AUTOSAR XML (schema 00050)
package /MICROSAR/NvM_swc/DataTypes
  impl type NvM_RequestResultType: compu {0=NVM_REQ_OK, 1=NVM_REQ_NOT_OK, 2=NVM_REQ_PENDING, 3=NVM_REQ_INTEGRITY_FAILED, 4=NVM_REQ_BLOCK_SKIPPED, 5=NVM_REQ_NV_INVALIDATED, 6=NVM_REQ_CANCELED, 7=NVM_REQ_REDUNDANCY_FAILED, 8=NVM_REQ_RESTORED_FROM_ROM}, range raw 0..8, implementation-data-type=uint8
  impl type NvM_BlockIdType: range raw 1..32767, implementation-data-type=uint16
  impl type NvM_ServiceIdType: compu {6=NVM_READ_BLOCK, 7=NVM_WRITE_BLOCK, 8=NVM_RESTORE_BLOCK_DEFAULTS, 9=NVM_ERASE_BLOCK, 11=NVM_INVALIDATE_NV_BLOCK, 12=NVM_READ_ALL}, range raw 6..12, implementation-data-type=uint8
package /MICROSAR/NvM_swc/Interfaces
  4 x client server interface, all with is-service=true, service-kind=NON-VOLATILE-RAM-MANAGER:
    NvMAdministration
      operation SetBlockProtection: possible-error=NvMAdministration/E_NOT_OK
        arg ProtectionEnabled: type=boolean, direction=IN
      error E_NOT_OK: error-code=1
    NvMService_AC3_SRBS_DS
      8 x operation, all with possible-error=NvMService_AC3_SRBS_DS/E_NOT_OK:
        GetErrorStatus
          arg ErrorStatus: type=NvM_RequestResultType, direction=OUT
        SetRamBlockStatus
          arg RamBlockStatus: type=boolean, direction=IN
        ReadBlock
          arg DstPtr: type=dtRef_VOID, direction=IN
        WriteBlock
          arg SrcPtr: type=dtRef_const_VOID, direction=IN
        SetDataIndex
          arg DataIndex: type=uint8, direction=IN
        GetDataIndex
          arg DataIndex: type=uint8, direction=OUT
        InvalidateNvBlock
        EraseBlock
      error E_NOT_OK: error-code=1
    NvMNotifyJobFinished
      operation JobFinished
        arg ServiceId: type=NvM_ServiceIdType, direction=IN
        arg JobResult: type=NvM_RequestResultType, direction=IN
    NvMService_AC3_SRBS_Defs
      7 x operation, all with possible-error=NvMService_AC3_SRBS_Defs/E_NOT_OK:
        GetErrorStatus
          arg ErrorStatus: type=NvM_RequestResultType, direction=OUT
        SetRamBlockStatus
          arg RamBlockStatus: type=boolean, direction=IN
        ReadBlock
          arg DstPtr: type=dtRef_VOID, direction=IN
        WriteBlock
          arg SrcPtr: type=dtRef_const_VOID, direction=IN
        RestoreBlockDefaults
          arg DstPtr: type=dtRef_VOID, direction=IN
        InvalidateNvBlock
        EraseBlock
      error E_NOT_OK: error-code=1
package /MICROSAR/NvM_swc/ComponentTypes
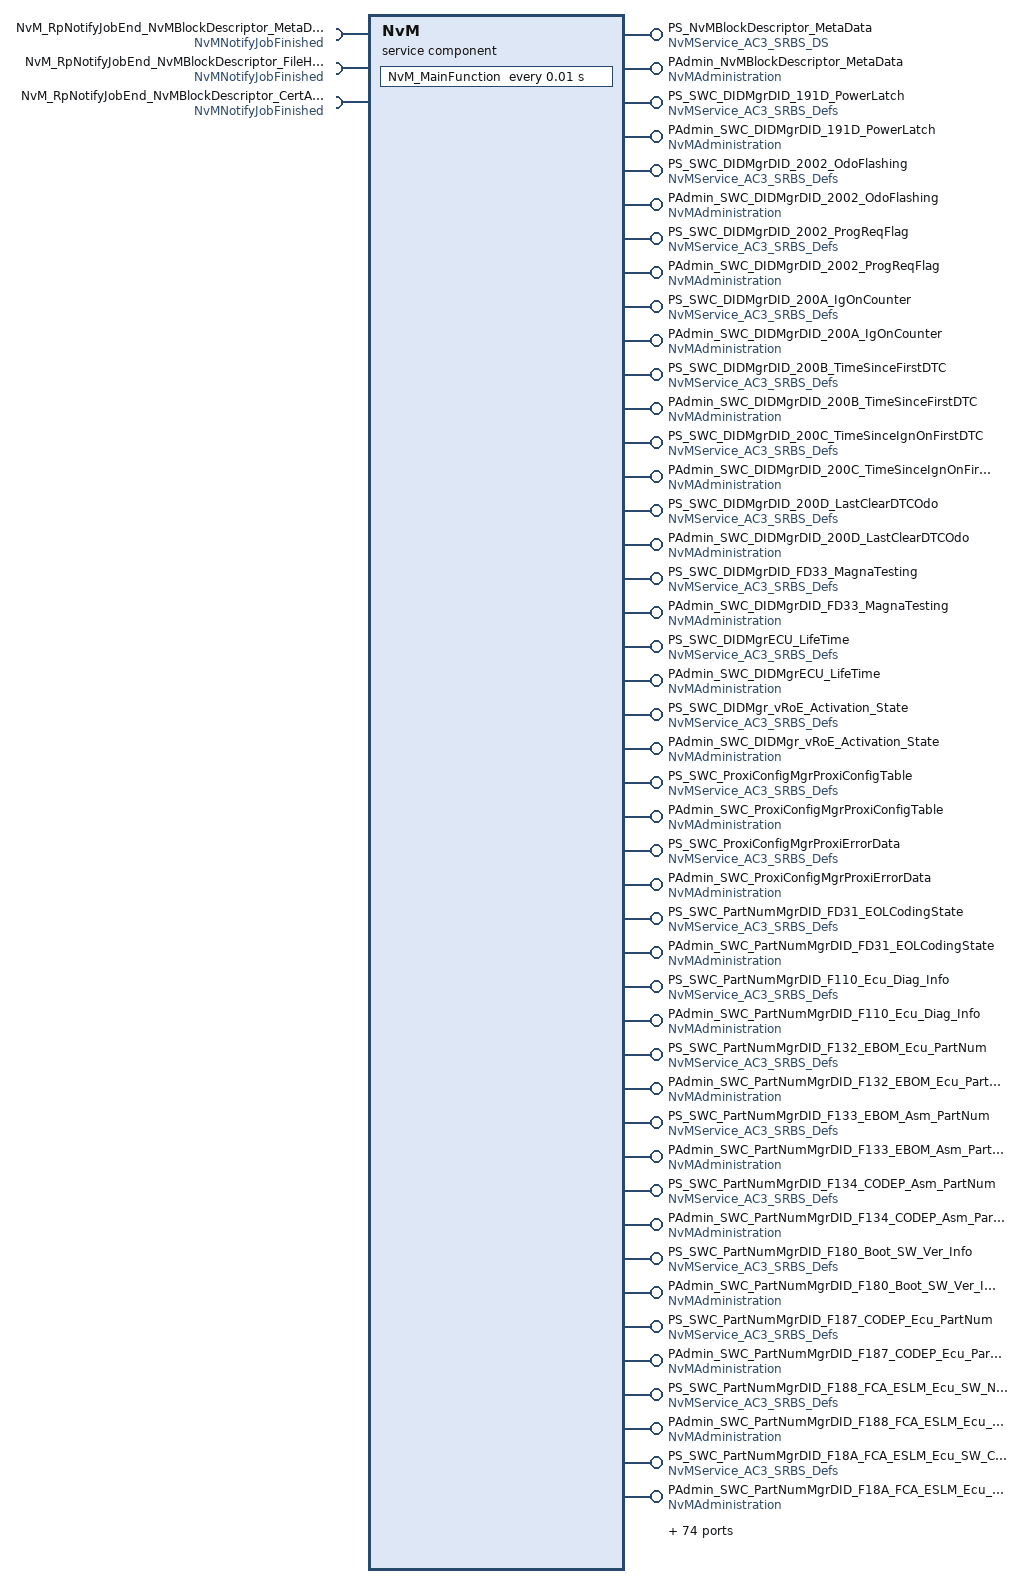
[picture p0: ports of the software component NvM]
  service sw component type NvM: category=SERVICE_COMPONENT
    provide port PS_NvMBlockDescriptor_MetaData: provided-interface=NvMService_AC3_SRBS_DS
    provide port PAdmin_NvMBlockDescriptor_MetaData: provided-interface=NvMAdministration
    require port NvM_RpNotifyJobEnd_NvMBlockDescriptor_MetaData: required-interface=NvMNotifyJobFinished
    86 x provide port:
      PS_SWC_DIDMgrDID_191D_PowerLatch: provided-interface=NvMService_AC3_SRBS_Defs
      PAdmin_SWC_DIDMgrDID_191D_PowerLatch: provided-interface=NvMAdministration
      PS_SWC_DIDMgrDID_2002_OdoFlashing: provided-interface=NvMService_AC3_SRBS_Defs
      PAdmin_SWC_DIDMgrDID_2002_OdoFlashing: provided-interface=NvMAdministration
      PS_SWC_DIDMgrDID_2002_ProgReqFlag: provided-interface=NvMService_AC3_SRBS_Defs
      PAdmin_SWC_DIDMgrDID_2002_ProgReqFlag: provided-interface=NvMAdministration
      PS_SWC_DIDMgrDID_200A_IgOnCounter: provided-interface=NvMService_AC3_SRBS_Defs
      PAdmin_SWC_DIDMgrDID_200A_IgOnCounter: provided-interface=NvMAdministration
      PS_SWC_DIDMgrDID_200B_TimeSinceFirstDTC: provided-interface=NvMService_AC3_SRBS_Defs
      PAdmin_SWC_DIDMgrDID_200B_TimeSinceFirstDTC: provided-interface=NvMAdministration
      PS_SWC_DIDMgrDID_200C_TimeSinceIgnOnFirstDTC: provided-interface=NvMService_AC3_SRBS_Defs
      PAdmin_SWC_DIDMgrDID_200C_TimeSinceIgnOnFirstDTC: provided-interface=NvMAdministration
      PS_SWC_DIDMgrDID_200D_LastClearDTCOdo: provided-interface=NvMService_AC3_SRBS_Defs
      PAdmin_SWC_DIDMgrDID_200D_LastClearDTCOdo: provided-interface=NvMAdministration
      PS_SWC_DIDMgrDID_FD33_MagnaTesting: provided-interface=NvMService_AC3_SRBS_Defs
      PAdmin_SWC_DIDMgrDID_FD33_MagnaTesting: provided-interface=NvMAdministration
      PS_SWC_DIDMgrECU_LifeTime: provided-interface=NvMService_AC3_SRBS_Defs
      PAdmin_SWC_DIDMgrECU_LifeTime: provided-interface=NvMAdministration
      PS_SWC_DIDMgr_vRoE_Activation_State: provided-interface=NvMService_AC3_SRBS_Defs
      PAdmin_SWC_DIDMgr_vRoE_Activation_State: provided-interface=NvMAdministration
      PS_SWC_ProxiConfigMgrProxiConfigTable: provided-interface=NvMService_AC3_SRBS_Defs
      PAdmin_SWC_ProxiConfigMgrProxiConfigTable: provided-interface=NvMAdministration
      PS_SWC_ProxiConfigMgrProxiErrorData: provided-interface=NvMService_AC3_SRBS_Defs
      PAdmin_SWC_ProxiConfigMgrProxiErrorData: provided-interface=NvMAdministration
      PS_SWC_PartNumMgrDID_FD31_EOLCodingState: provided-interface=NvMService_AC3_SRBS_Defs
      PAdmin_SWC_PartNumMgrDID_FD31_EOLCodingState: provided-interface=NvMAdministration
      PS_SWC_PartNumMgrDID_F110_Ecu_Diag_Info: provided-interface=NvMService_AC3_SRBS_Defs
      PAdmin_SWC_PartNumMgrDID_F110_Ecu_Diag_Info: provided-interface=NvMAdministration
      PS_SWC_PartNumMgrDID_F132_EBOM_Ecu_PartNum: provided-interface=NvMService_AC3_SRBS_Defs
      PAdmin_SWC_PartNumMgrDID_F132_EBOM_Ecu_PartNum: provided-interface=NvMAdministration
      PS_SWC_PartNumMgrDID_F133_EBOM_Asm_PartNum: provided-interface=NvMService_AC3_SRBS_Defs
      PAdmin_SWC_PartNumMgrDID_F133_EBOM_Asm_PartNum: provided-interface=NvMAdministration
      PS_SWC_PartNumMgrDID_F134_CODEP_Asm_PartNum: provided-interface=NvMService_AC3_SRBS_Defs
      PAdmin_SWC_PartNumMgrDID_F134_CODEP_Asm_PartNum: provided-interface=NvMAdministration
      PS_SWC_PartNumMgrDID_F180_Boot_SW_Ver_Info: provided-interface=NvMService_AC3_SRBS_Defs
      PAdmin_SWC_PartNumMgrDID_F180_Boot_SW_Ver_Info: provided-interface=NvMAdministration
      PS_SWC_PartNumMgrDID_F187_CODEP_Ecu_PartNum: provided-interface=NvMService_AC3_SRBS_Defs
      PAdmin_SWC_PartNumMgrDID_F187_CODEP_Ecu_PartNum: provided-interface=NvMAdministration
      PS_SWC_PartNumMgrDID_F188_FCA_ESLM_Ecu_SW_Num: provided-interface=NvMService_AC3_SRBS_Defs
      PAdmin_SWC_PartNumMgrDID_F188_FCA_ESLM_Ecu_SW_Num: provided-interface=NvMAdministration
      PS_SWC_PartNumMgrDID_F18A_FCA_ESLM_Ecu_SW_Cal_Num: provided-interface=NvMService_AC3_SRBS_Defs
      PAdmin_SWC_PartNumMgrDID_F18A_FCA_ESLM_Ecu_SW_Cal_Num: provided-interface=NvMAdministration
      PS_SWC_PartNumMgrDID_F18B_FCA_ESLM_ECU_SW_App_Num: provided-interface=NvMService_AC3_SRBS_Defs
      PAdmin_SWC_PartNumMgrDID_F18B_FCA_ESLM_ECU_SW_App_Num: provided-interface=NvMAdministration
      PS_SWC_PartNumMgrDID_F194_Supplier_Ecu_SW_PartNum: provided-interface=NvMService_AC3_SRBS_Defs
      PAdmin_SWC_PartNumMgrDID_F194_Supplier_Ecu_SW_PartNum: provided-interface=NvMAdministration
      PS_SWC_PartNumMgrDID_F195_Supplier_Ecu_SW_VerNum: provided-interface=NvMService_AC3_SRBS_Defs
      PAdmin_SWC_PartNumMgrDID_F195_Supplier_Ecu_SW_VerNum: provided-interface=NvMAdministration
      PS_CalDataProviderSVSCamCurrentCalibData: provided-interface=NvMService_AC3_SRBS_Defs
      PAdmin_CalDataProviderSVSCamCurrentCalibData: provided-interface=NvMAdministration
      PS_CalDataProviderSVSCamEOLCalibData: provided-interface=NvMService_AC3_SRBS_Defs
      PAdmin_CalDataProviderSVSCamEOLCalibData: provided-interface=NvMAdministration
      PS_CalDataProviderSVSCamOCCalibData: provided-interface=NvMService_AC3_SRBS_Defs
      PAdmin_CalDataProviderSVSCamOCCalibData: provided-interface=NvMAdministration
      PS_CalDataProviderSVSCamSCCalibData: provided-interface=NvMService_AC3_SRBS_Defs
      PAdmin_CalDataProviderSVSCamSCCalibData: provided-interface=NvMAdministration
      PS_SWC_PartNumMgrUssSensorMarrData: provided-interface=NvMService_AC3_SRBS_Defs
      PAdmin_SWC_PartNumMgrUssSensorMarrData: provided-interface=NvMAdministration
      PS_SWC_DIDMgrDID_FD01_PrevCalibDataCopy: provided-interface=NvMService_AC3_SRBS_Defs
      PAdmin_SWC_DIDMgrDID_FD01_PrevCalibDataCopy: provided-interface=NvMAdministration
      PS_SWC_DIDMgrDID_FD42_FailsafeDebug: provided-interface=NvMService_AC3_SRBS_Defs
      PAdmin_SWC_DIDMgrDID_FD42_FailsafeDebug: provided-interface=NvMAdministration
      PS_SWC_DIDMgrDID_RearBrakeEvent: provided-interface=NvMService_AC3_SRBS_Defs
      PAdmin_SWC_DIDMgrDID_RearBrakeEvent: provided-interface=NvMAdministration
      PS_SWC_DIDMgrDID_SPMAbrtEvent: provided-interface=NvMService_AC3_SRBS_Defs
      PAdmin_SWC_DIDMgrDID_SPMAbrtEvent: provided-interface=NvMAdministration
      PS_CDD_IPCHandlerFeatureAP_HMI_NvMData: provided-interface=NvMService_AC3_SRBS_Defs
      PAdmin_CDD_IPCHandlerFeatureAP_HMI_NvMData: provided-interface=NvMAdministration
      PS_SWC_DIDMgrDID_FD86_FunctionalSettings: provided-interface=NvMService_AC3_SRBS_Defs
      PAdmin_SWC_DIDMgrDID_FD86_FunctionalSettings: provided-interface=NvMAdministration
      PS_SWC_DIDMgrDID_2939_WakeupReason: provided-interface=NvMService_AC3_SRBS_Defs
      PAdmin_SWC_DIDMgrDID_2939_WakeupReason: provided-interface=NvMAdministration
      PS_SWC_DIDMgrDID_FDF0_SleepProcess: provided-interface=NvMService_AC3_SRBS_Defs
      PAdmin_SWC_DIDMgrDID_FDF0_SleepProcess: provided-interface=NvMAdministration
      PS_SWC_RIDMgrDID_5201_PlantModeStatus: provided-interface=NvMService_AC3_SRBS_Defs
      PAdmin_SWC_RIDMgrDID_5201_PlantModeStatus: provided-interface=NvMAdministration
      PS_SWC_RIDMgrVIN_CurrentVal: provided-interface=NvMService_AC3_SRBS_Defs
      PAdmin_SWC_RIDMgrVIN_CurrentVal: provided-interface=NvMAdministration
      PS_SWC_RIDMgrVIN_Lock: provided-interface=NvMService_AC3_SRBS_Defs
      PAdmin_SWC_RIDMgrVIN_Lock: provided-interface=NvMAdministration
      PS_SWC_RIDMgrVIN_OdometerCnt: provided-interface=NvMService_AC3_SRBS_Defs
      PAdmin_SWC_RIDMgrVIN_OdometerCnt: provided-interface=NvMAdministration
      PS_SWC_RIDMgrVIN_OriginalVal: provided-interface=NvMService_AC3_SRBS_Defs
      PAdmin_SWC_RIDMgrVIN_OriginalVal: provided-interface=NvMAdministration
      PS_NvMBlockDescriptor_FileHeader: provided-interface=NvMService_AC3_SRBS_DS
      PAdmin_NvMBlockDescriptor_FileHeader: provided-interface=NvMAdministration
    require port NvM_RpNotifyJobEnd_NvMBlockDescriptor_FileHeader: required-interface=NvMNotifyJobFinished
    require port NvM_RpNotifyJobEnd_NvMBlockDescriptor_CertAccessInfo: required-interface=NvMNotifyJobFinished
    30 x provide port:
      PS_CDD_IPCHandlerFPA_SlotData: provided-interface=NvMService_AC3_SRBS_Defs
      PAdmin_CDD_IPCHandlerFPA_SlotData: provided-interface=NvMAdministration
      PS_CDD_CryptoMgrNvMBlockDescriptor_SecAccessDelayFlag: provided-interface=NvMService_AC3_SRBS_Defs
      PAdmin_CDD_CryptoMgrNvMBlockDescriptor_SecAccessDelayFlag: provided-interface=NvMAdministration
      PS_CDD_CryptoMgrNvMBlockDescriptor_SecAccessInvalidCount: provided-interface=NvMService_AC3_SRBS_Defs
      PAdmin_CDD_CryptoMgrNvMBlockDescriptor_SecAccessInvalidCount: provided-interface=NvMAdministration
      PS_NvMBlockDescriptor_CertAccessInfo: provided-interface=NvMService_AC3_SRBS_DS
      PAdmin_NvMBlockDescriptor_CertAccessInfo: provided-interface=NvMAdministration
      PS_CDD_CryptoMgrNvMBlockDescriptor_SecureLogGroup1: provided-interface=NvMService_AC3_SRBS_Defs
      PAdmin_CDD_CryptoMgrNvMBlockDescriptor_SecureLogGroup1: provided-interface=NvMAdministration
      PS_CDD_CryptoMgrNvMBlockDescriptor_SecureLogGroup2: provided-interface=NvMService_AC3_SRBS_Defs
      PAdmin_CDD_CryptoMgrNvMBlockDescriptor_SecureLogGroup2: provided-interface=NvMAdministration
      PS_Safety_GuardSafeStat2_ResetReason: provided-interface=NvMService_AC3_SRBS_Defs
      PAdmin_Safety_GuardSafeStat2_ResetReason: provided-interface=NvMAdministration
      PS_CalDataProviderFrontCamSerialNumber: provided-interface=NvMService_AC3_SRBS_Defs
      PAdmin_CalDataProviderFrontCamSerialNumber: provided-interface=NvMAdministration
      PS_CalDataProviderLeftCamSerialNumber: provided-interface=NvMService_AC3_SRBS_Defs
      PAdmin_CalDataProviderLeftCamSerialNumber: provided-interface=NvMAdministration
      PS_CalDataProviderRearCamSerialNumber: provided-interface=NvMService_AC3_SRBS_Defs
      PAdmin_CalDataProviderRearCamSerialNumber: provided-interface=NvMAdministration
      PS_CalDataProviderRightCamSerialNumber: provided-interface=NvMService_AC3_SRBS_Defs
      PAdmin_CalDataProviderRightCamSerialNumber: provided-interface=NvMAdministration
      PS_CDD_SafetyCDD_PMICLastResetReason_BISTStatus: provided-interface=NvMService_AC3_SRBS_Defs
      PAdmin_CDD_SafetyCDD_PMICLastResetReason_BISTStatus: provided-interface=NvMAdministration
      PS_SWC_DIDMgrDID_FD74_BuffMarkCompErr: provided-interface=NvMService_AC3_SRBS_Defs
      PAdmin_SWC_DIDMgrDID_FD74_BuffMarkCompErr: provided-interface=NvMAdministration
      PS_SWC_DIDMgrDID_FD74_PHY_TuningErr: provided-interface=NvMService_AC3_SRBS_Defs
      PAdmin_SWC_DIDMgrDID_FD74_PHY_TuningErr: provided-interface=NvMAdministration
      PS_SWC_DTCMgrDTC_APARequestSts_PAMRequestSts: provided-interface=NvMService_AC3_SRBS_Defs
      PAdmin_SWC_DTCMgrDTC_APARequestSts_PAMRequestSts: provided-interface=NvMAdministration
    behavior NvMInternalBehavior: handle-termination-and-restart=NO-SUPPORT
      timing event Timer_NvM_MainFunction: start-on-event=NvM_MainFunction, period=0.01
      475 x operation invoked event:
        OpEventGetErrorStatus_GetErrorStatus_PS_NvMBlockDescriptor_MetaData: start-on-event=GetErrorStatus, operation=PS_NvMBlockDescriptor_MetaData.GetErrorStatus
        OpEventSetRamBlockStatus_SetRamBlockStatus_PS_NvMBlockDescriptor_MetaData: start-on-event=SetRamBlockStatus, operation=PS_NvMBlockDescriptor_MetaData.SetRamBlockStatus
        OpEventReadBlock_ReadBlock_PS_NvMBlockDescriptor_MetaData: start-on-event=ReadBlock, operation=PS_NvMBlockDescriptor_MetaData.ReadBlock
        OpEventWriteBlock_WriteBlock_PS_NvMBlockDescriptor_MetaData: start-on-event=WriteBlock, operation=PS_NvMBlockDescriptor_MetaData.WriteBlock
        OpEventSetDataIndex_SetDataIndex_PS_NvMBlockDescriptor_MetaData: start-on-event=SetDataIndex, operation=PS_NvMBlockDescriptor_MetaData.SetDataIndex
        OpEventGetDataIndex_GetDataIndex_PS_NvMBlockDescriptor_MetaData: start-on-event=GetDataIndex, operation=PS_NvMBlockDescriptor_MetaData.GetDataIndex
        OpEventInvalidateNvBlock_InvalidateNvBlock_PS_NvMBlockDescriptor_MetaData: start-on-event=InvalidateNvBlock, operation=PS_NvMBlockDescriptor_MetaData.InvalidateNvBlock
        OpEventEraseBlock_EraseBlock_PS_NvMBlockDescriptor_MetaData: start-on-event=EraseBlock, operation=PS_NvMBlockDescriptor_MetaData.EraseBlock
        OpEventSetBlockProtection_SetBlockProtection_PAdmin_NvMBlockDescriptor_MetaData: start-on-event=SetBlockProtection, operation=PAdmin_NvMBlockDescriptor_MetaData.SetBlockProtection
        OpEventGetErrorStatus_GetErrorStatus_PS_SWC_DIDMgrDID_191D_PowerLatch: start-on-event=GetErrorStatus, operation=PS_SWC_DIDMgrDID_191D_PowerLatch.GetErrorStatus
        OpEventGetErrorStatus_GetErrorStatus_PS_SWC_DIDMgrDID_2002_OdoFlashing: start-on-event=GetErrorStatus, operation=PS_SWC_DIDMgrDID_2002_OdoFlashing.GetErrorStatus
        OpEventGetErrorStatus_GetErrorStatus_PS_SWC_DIDMgrDID_2002_ProgReqFlag: start-on-event=GetErrorStatus, operation=PS_SWC_DIDMgrDID_2002_ProgReqFlag.GetErrorStatus
        OpEventGetErrorStatus_GetErrorStatus_PS_SWC_DIDMgrDID_200A_IgOnCounter: start-on-event=GetErrorStatus, operation=PS_SWC_DIDMgrDID_200A_IgOnCounter.GetErrorStatus
        OpEventGetErrorStatus_GetErrorStatus_PS_SWC_DIDMgrDID_200B_TimeSinceFirstDTC: start-on-event=GetErrorStatus, operation=PS_SWC_DIDMgrDID_200B_TimeSinceFirstDTC.GetErrorStatus
        OpEventGetErrorStatus_GetErrorStatus_PS_SWC_DIDMgrDID_200C_TimeSinceIgnOnFirstDTC: start-on-event=GetErrorStatus, operation=PS_SWC_DIDMgrDID_200C_TimeSinceIgnOnFirstDTC.GetErrorStatus
        OpEventGetErrorStatus_GetErrorStatus_PS_SWC_DIDMgrDID_200D_LastClearDTCOdo: start-on-event=GetErrorStatus, operation=PS_SWC_DIDMgrDID_200D_LastClearDTCOdo.GetErrorStatus
        OpEventGetErrorStatus_GetErrorStatus_PS_SWC_DIDMgrDID_FD33_MagnaTesting: start-on-event=GetErrorStatus, operation=PS_SWC_DIDMgrDID_FD33_MagnaTesting.GetErrorStatus
        OpEventGetErrorStatus_GetErrorStatus_PS_SWC_DIDMgrECU_LifeTime: start-on-event=GetErrorStatus, operation=PS_SWC_DIDMgrECU_LifeTime.GetErrorStatus
        OpEventGetErrorStatus_GetErrorStatus_PS_SWC_DIDMgr_vRoE_Activation_State: start-on-event=GetErrorStatus, operation=PS_SWC_DIDMgr_vRoE_Activation_State.GetErrorStatus
        OpEventSetRamBlockStatus_SetRamBlockStatus_PS_SWC_DIDMgrDID_191D_PowerLatch: start-on-event=SetRamBlockStatus, operation=PS_SWC_DIDMgrDID_191D_PowerLatch.SetRamBlockStatus
        OpEventSetRamBlockStatus_SetRamBlockStatus_PS_SWC_DIDMgrDID_2002_OdoFlashing: start-on-event=SetRamBlockStatus, operation=PS_SWC_DIDMgrDID_2002_OdoFlashing.SetRamBlockStatus
        OpEventSetRamBlockStatus_SetRamBlockStatus_PS_SWC_DIDMgrDID_2002_ProgReqFlag: start-on-event=SetRamBlockStatus, operation=PS_SWC_DIDMgrDID_2002_ProgReqFlag.SetRamBlockStatus
        OpEventSetRamBlockStatus_SetRamBlockStatus_PS_SWC_DIDMgrDID_200A_IgOnCounter: start-on-event=SetRamBlockStatus, operation=PS_SWC_DIDMgrDID_200A_IgOnCounter.SetRamBlockStatus
        OpEventSetRamBlockStatus_SetRamBlockStatus_PS_SWC_DIDMgrDID_200B_TimeSinceFirstDTC: start-on-event=SetRamBlockStatus, operation=PS_SWC_DIDMgrDID_200B_TimeSinceFirstDTC.SetRamBlockStatus
        OpEventSetRamBlockStatus_SetRamBlockStatus_PS_SWC_DIDMgrDID_200C_TimeSinceIgnOnFirstDTC: start-on-event=SetRamBlockStatus, operation=PS_SWC_DIDMgrDID_200C_TimeSinceIgnOnFirstDTC.SetRamBlockStatus
        OpEventSetRamBlockStatus_SetRamBlockStatus_PS_SWC_DIDMgrDID_200D_LastClearDTCOdo: start-on-event=SetRamBlockStatus, operation=PS_SWC_DIDMgrDID_200D_LastClearDTCOdo.SetRamBlockStatus
        OpEventSetRamBlockStatus_SetRamBlockStatus_PS_SWC_DIDMgrDID_FD33_MagnaTesting: start-on-event=SetRamBlockStatus, operation=PS_SWC_DIDMgrDID_FD33_MagnaTesting.SetRamBlockStatus
        OpEventSetRamBlockStatus_SetRamBlockStatus_PS_SWC_DIDMgrECU_LifeTime: start-on-event=SetRamBlockStatus, operation=PS_SWC_DIDMgrECU_LifeTime.SetRamBlockStatus
        OpEventSetRamBlockStatus_SetRamBlockStatus_PS_SWC_DIDMgr_vRoE_Activation_State: start-on-event=SetRamBlockStatus, operation=PS_SWC_DIDMgr_vRoE_Activation_State.SetRamBlockStatus
        OpEventReadBlock_ReadBlock_PS_SWC_DIDMgrDID_191D_PowerLatch: start-on-event=ReadBlock, operation=PS_SWC_DIDMgrDID_191D_PowerLatch.ReadBlock
        OpEventReadBlock_ReadBlock_PS_SWC_DIDMgrDID_2002_OdoFlashing: start-on-event=ReadBlock, operation=PS_SWC_DIDMgrDID_2002_OdoFlashing.ReadBlock
        OpEventReadBlock_ReadBlock_PS_SWC_DIDMgrDID_2002_ProgReqFlag: start-on-event=ReadBlock, operation=PS_SWC_DIDMgrDID_2002_ProgReqFlag.ReadBlock
        OpEventReadBlock_ReadBlock_PS_SWC_DIDMgrDID_200A_IgOnCounter: start-on-event=ReadBlock, operation=PS_SWC_DIDMgrDID_200A_IgOnCounter.ReadBlock
        OpEventReadBlock_ReadBlock_PS_SWC_DIDMgrDID_200B_TimeSinceFirstDTC: start-on-event=ReadBlock, operation=PS_SWC_DIDMgrDID_200B_TimeSinceFirstDTC.ReadBlock
        OpEventReadBlock_ReadBlock_PS_SWC_DIDMgrDID_200C_TimeSinceIgnOnFirstDTC: start-on-event=ReadBlock, operation=PS_SWC_DIDMgrDID_200C_TimeSinceIgnOnFirstDTC.ReadBlock
        OpEventReadBlock_ReadBlock_PS_SWC_DIDMgrDID_200D_LastClearDTCOdo: start-on-event=ReadBlock, operation=PS_SWC_DIDMgrDID_200D_LastClearDTCOdo.ReadBlock
        OpEventReadBlock_ReadBlock_PS_SWC_DIDMgrDID_FD33_MagnaTesting: start-on-event=ReadBlock, operation=PS_SWC_DIDMgrDID_FD33_MagnaTesting.ReadBlock
        OpEventReadBlock_ReadBlock_PS_SWC_DIDMgrECU_LifeTime: start-on-event=ReadBlock, operation=PS_SWC_DIDMgrECU_LifeTime.ReadBlock
        OpEventReadBlock_ReadBlock_PS_SWC_DIDMgr_vRoE_Activation_State: start-on-event=ReadBlock, operation=PS_SWC_DIDMgr_vRoE_Activation_State.ReadBlock
        OpEventWriteBlock_WriteBlock_PS_SWC_DIDMgrDID_191D_PowerLatch: start-on-event=WriteBlock, operation=PS_SWC_DIDMgrDID_191D_PowerLatch.WriteBlock
        OpEventWriteBlock_WriteBlock_PS_SWC_DIDMgrDID_2002_OdoFlashing: start-on-event=WriteBlock, operation=PS_SWC_DIDMgrDID_2002_OdoFlashing.WriteBlock
        OpEventWriteBlock_WriteBlock_PS_SWC_DIDMgrDID_2002_ProgReqFlag: start-on-event=WriteBlock, operation=PS_SWC_DIDMgrDID_2002_ProgReqFlag.WriteBlock
        OpEventWriteBlock_WriteBlock_PS_SWC_DIDMgrDID_200A_IgOnCounter: start-on-event=WriteBlock, operation=PS_SWC_DIDMgrDID_200A_IgOnCounter.WriteBlock
        OpEventWriteBlock_WriteBlock_PS_SWC_DIDMgrDID_200B_TimeSinceFirstDTC: start-on-event=WriteBlock, operation=PS_SWC_DIDMgrDID_200B_TimeSinceFirstDTC.WriteBlock
        OpEventWriteBlock_WriteBlock_PS_SWC_DIDMgrDID_200C_TimeSinceIgnOnFirstDTC: start-on-event=WriteBlock, operation=PS_SWC_DIDMgrDID_200C_TimeSinceIgnOnFirstDTC.WriteBlock
        OpEventWriteBlock_WriteBlock_PS_SWC_DIDMgrDID_200D_LastClearDTCOdo: start-on-event=WriteBlock, operation=PS_SWC_DIDMgrDID_200D_LastClearDTCOdo.WriteBlock
        OpEventWriteBlock_WriteBlock_PS_SWC_DIDMgrDID_FD33_MagnaTesting: start-on-event=WriteBlock, operation=PS_SWC_DIDMgrDID_FD33_MagnaTesting.WriteBlock
        OpEventWriteBlock_WriteBlock_PS_SWC_DIDMgrECU_LifeTime: start-on-event=WriteBlock, operation=PS_SWC_DIDMgrECU_LifeTime.WriteBlock
        OpEventWriteBlock_WriteBlock_PS_SWC_DIDMgr_vRoE_Activation_State: start-on-event=WriteBlock, operation=PS_SWC_DIDMgr_vRoE_Activation_State.WriteBlock
        OpEventInvalidateNvBlock_InvalidateNvBlock_PS_SWC_DIDMgrDID_191D_PowerLatch: start-on-event=InvalidateNvBlock, operation=PS_SWC_DIDMgrDID_191D_PowerLatch.InvalidateNvBlock
        OpEventInvalidateNvBlock_InvalidateNvBlock_PS_SWC_DIDMgrDID_2002_OdoFlashing: start-on-event=InvalidateNvBlock, operation=PS_SWC_DIDMgrDID_2002_OdoFlashing.InvalidateNvBlock
        OpEventInvalidateNvBlock_InvalidateNvBlock_PS_SWC_DIDMgrDID_2002_ProgReqFlag: start-on-event=InvalidateNvBlock, operation=PS_SWC_DIDMgrDID_2002_ProgReqFlag.InvalidateNvBlock
        OpEventInvalidateNvBlock_InvalidateNvBlock_PS_SWC_DIDMgrDID_200A_IgOnCounter: start-on-event=InvalidateNvBlock, operation=PS_SWC_DIDMgrDID_200A_IgOnCounter.InvalidateNvBlock
        OpEventInvalidateNvBlock_InvalidateNvBlock_PS_SWC_DIDMgrDID_200B_TimeSinceFirstDTC: start-on-event=InvalidateNvBlock, operation=PS_SWC_DIDMgrDID_200B_TimeSinceFirstDTC.InvalidateNvBlock
        OpEventInvalidateNvBlock_InvalidateNvBlock_PS_SWC_DIDMgrDID_200C_TimeSinceIgnOnFirstDTC: start-on-event=InvalidateNvBlock, operation=PS_SWC_DIDMgrDID_200C_TimeSinceIgnOnFirstDTC.InvalidateNvBlock
        OpEventInvalidateNvBlock_InvalidateNvBlock_PS_SWC_DIDMgrDID_200D_LastClearDTCOdo: start-on-event=InvalidateNvBlock, operation=PS_SWC_DIDMgrDID_200D_LastClearDTCOdo.InvalidateNvBlock
        OpEventInvalidateNvBlock_InvalidateNvBlock_PS_SWC_DIDMgrDID_FD33_MagnaTesting: start-on-event=InvalidateNvBlock, operation=PS_SWC_DIDMgrDID_FD33_MagnaTesting.InvalidateNvBlock
        OpEventInvalidateNvBlock_InvalidateNvBlock_PS_SWC_DIDMgrECU_LifeTime: start-on-event=InvalidateNvBlock, operation=PS_SWC_DIDMgrECU_LifeTime.InvalidateNvBlock
        OpEventInvalidateNvBlock_InvalidateNvBlock_PS_SWC_DIDMgr_vRoE_Activation_State: start-on-event=InvalidateNvBlock, operation=PS_SWC_DIDMgr_vRoE_Activation_State.InvalidateNvBlock
        OpEventEraseBlock_EraseBlock_PS_SWC_DIDMgrDID_191D_PowerLatch: start-on-event=EraseBlock, operation=PS_SWC_DIDMgrDID_191D_PowerLatch.EraseBlock
        OpEventEraseBlock_EraseBlock_PS_SWC_DIDMgrDID_2002_OdoFlashing: start-on-event=EraseBlock, operation=PS_SWC_DIDMgrDID_2002_OdoFlashing.EraseBlock
        OpEventEraseBlock_EraseBlock_PS_SWC_DIDMgrDID_2002_ProgReqFlag: start-on-event=EraseBlock, operation=PS_SWC_DIDMgrDID_2002_ProgReqFlag.EraseBlock
        OpEventEraseBlock_EraseBlock_PS_SWC_DIDMgrDID_200A_IgOnCounter: start-on-event=EraseBlock, operation=PS_SWC_DIDMgrDID_200A_IgOnCounter.EraseBlock
        OpEventEraseBlock_EraseBlock_PS_SWC_DIDMgrDID_200B_TimeSinceFirstDTC: start-on-event=EraseBlock, operation=PS_SWC_DIDMgrDID_200B_TimeSinceFirstDTC.EraseBlock
        OpEventEraseBlock_EraseBlock_PS_SWC_DIDMgrDID_200C_TimeSinceIgnOnFirstDTC: start-on-event=EraseBlock, operation=PS_SWC_DIDMgrDID_200C_TimeSinceIgnOnFirstDTC.EraseBlock
        OpEventEraseBlock_EraseBlock_PS_SWC_DIDMgrDID_200D_LastClearDTCOdo: start-on-event=EraseBlock, operation=PS_SWC_DIDMgrDID_200D_LastClearDTCOdo.EraseBlock
        OpEventEraseBlock_EraseBlock_PS_SWC_DIDMgrDID_FD33_MagnaTesting: start-on-event=EraseBlock, operation=PS_SWC_DIDMgrDID_FD33_MagnaTesting.EraseBlock
        OpEventEraseBlock_EraseBlock_PS_SWC_DIDMgrECU_LifeTime: start-on-event=EraseBlock, operation=PS_SWC_DIDMgrECU_LifeTime.EraseBlock
        OpEventEraseBlock_EraseBlock_PS_SWC_DIDMgr_vRoE_Activation_State: start-on-event=EraseBlock, operation=PS_SWC_DIDMgr_vRoE_Activation_State.EraseBlock
        OpEventSetBlockProtection_SetBlockProtection_PAdmin_SWC_DIDMgrDID_191D_PowerLatch: start-on-event=SetBlockProtection, operation=PAdmin_SWC_DIDMgrDID_191D_PowerLatch.SetBlockProtection
        OpEventSetBlockProtection_SetBlockProtection_PAdmin_SWC_DIDMgrDID_2002_OdoFlashing: start-on-event=SetBlockProtection, operation=PAdmin_SWC_DIDMgrDID_2002_OdoFlashing.SetBlockProtection
        OpEventSetBlockProtection_SetBlockProtection_PAdmin_SWC_DIDMgrDID_2002_ProgReqFlag: start-on-event=SetBlockProtection, operation=PAdmin_SWC_DIDMgrDID_2002_ProgReqFlag.SetBlockProtection
        OpEventSetBlockProtection_SetBlockProtection_PAdmin_SWC_DIDMgrDID_200A_IgOnCounter: start-on-event=SetBlockProtection, operation=PAdmin_SWC_DIDMgrDID_200A_IgOnCounter.SetBlockProtection
        OpEventSetBlockProtection_SetBlockProtection_PAdmin_SWC_DIDMgrDID_200B_TimeSinceFirstDTC: start-on-event=SetBlockProtection, operation=PAdmin_SWC_DIDMgrDID_200B_TimeSinceFirstDTC.SetBlockProtection
        OpEventSetBlockProtection_SetBlockProtection_PAdmin_SWC_DIDMgrDID_200C_TimeSinceIgnOnFirstDTC: start-on-event=SetBlockProtection, operation=PAdmin_SWC_DIDMgrDID_200C_TimeSinceIgnOnFirstDTC.SetBlockProtection
        OpEventSetBlockProtection_SetBlockProtection_PAdmin_SWC_DIDMgrDID_200D_LastClearDTCOdo: start-on-event=SetBlockProtection, operation=PAdmin_SWC_DIDMgrDID_200D_LastClearDTCOdo.SetBlockProtection
        OpEventSetBlockProtection_SetBlockProtection_PAdmin_SWC_DIDMgrDID_FD33_MagnaTesting: start-on-event=SetBlockProtection, operation=PAdmin_SWC_DIDMgrDID_FD33_MagnaTesting.SetBlockProtection
        OpEventSetBlockProtection_SetBlockProtection_PAdmin_SWC_DIDMgrECU_LifeTime: start-on-event=SetBlockProtection, operation=PAdmin_SWC_DIDMgrECU_LifeTime.SetBlockProtection
        OpEventSetBlockProtection_SetBlockProtection_PAdmin_SWC_DIDMgr_vRoE_Activation_State: start-on-event=SetBlockProtection, operation=PAdmin_SWC_DIDMgr_vRoE_Activation_State.SetBlockProtection
        OpEventRestoreBlockDefaults_RestoreBlockDefaults_PS_SWC_DIDMgrDID_191D_PowerLatch: start-on-event=RestoreBlockDefaults, operation=PS_SWC_DIDMgrDID_191D_PowerLatch.RestoreBlockDefaults
        OpEventRestoreBlockDefaults_RestoreBlockDefaults_PS_SWC_DIDMgrDID_2002_OdoFlashing: start-on-event=RestoreBlockDefaults, operation=PS_SWC_DIDMgrDID_2002_OdoFlashing.RestoreBlockDefaults
        OpEventRestoreBlockDefaults_RestoreBlockDefaults_PS_SWC_DIDMgrDID_2002_ProgReqFlag: start-on-event=RestoreBlockDefaults, operation=PS_SWC_DIDMgrDID_2002_ProgReqFlag.RestoreBlockDefaults
        OpEventRestoreBlockDefaults_RestoreBlockDefaults_PS_SWC_DIDMgrDID_200A_IgOnCounter: start-on-event=RestoreBlockDefaults, operation=PS_SWC_DIDMgrDID_200A_IgOnCounter.RestoreBlockDefaults
        OpEventRestoreBlockDefaults_RestoreBlockDefaults_PS_SWC_DIDMgrDID_200B_TimeSinceFirstDTC: start-on-event=RestoreBlockDefaults, operation=PS_SWC_DIDMgrDID_200B_TimeSinceFirstDTC.RestoreBlockDefaults
        OpEventRestoreBlockDefaults_RestoreBlockDefaults_PS_SWC_DIDMgrDID_200C_TimeSinceIgnOnFirstDTC: start-on-event=RestoreBlockDefaults, operation=PS_SWC_DIDMgrDID_200C_TimeSinceIgnOnFirstDTC.RestoreBlockDefaults
        OpEventRestoreBlockDefaults_RestoreBlockDefaults_PS_SWC_DIDMgrDID_200D_LastClearDTCOdo: start-on-event=RestoreBlockDefaults, operation=PS_SWC_DIDMgrDID_200D_LastClearDTCOdo.RestoreBlockDefaults
        OpEventRestoreBlockDefaults_RestoreBlockDefaults_PS_SWC_DIDMgrDID_FD33_MagnaTesting: start-on-event=RestoreBlockDefaults, operation=PS_SWC_DIDMgrDID_FD33_MagnaTesting.RestoreBlockDefaults
        OpEventRestoreBlockDefaults_RestoreBlockDefaults_PS_SWC_DIDMgrECU_LifeTime: start-on-event=RestoreBlockDefaults, operation=PS_SWC_DIDMgrECU_LifeTime.RestoreBlockDefaults
        OpEventRestoreBlockDefaults_RestoreBlockDefaults_PS_SWC_DIDMgr_vRoE_Activation_State: start-on-event=RestoreBlockDefaults, operation=PS_SWC_DIDMgr_vRoE_Activation_State.RestoreBlockDefaults
        OpEventGetErrorStatus_GetErrorStatus_PS_SWC_ProxiConfigMgrProxiConfigTable: start-on-event=GetErrorStatus, operation=PS_SWC_ProxiConfigMgrProxiConfigTable.GetErrorStatus
        OpEventGetErrorStatus_GetErrorStatus_PS_SWC_ProxiConfigMgrProxiErrorData: start-on-event=GetErrorStatus, operation=PS_SWC_ProxiConfigMgrProxiErrorData.GetErrorStatus
        OpEventSetRamBlockStatus_SetRamBlockStatus_PS_SWC_ProxiConfigMgrProxiConfigTable: start-on-event=SetRamBlockStatus, operation=PS_SWC_ProxiConfigMgrProxiConfigTable.SetRamBlockStatus
        OpEventSetRamBlockStatus_SetRamBlockStatus_PS_SWC_ProxiConfigMgrProxiErrorData: start-on-event=SetRamBlockStatus, operation=PS_SWC_ProxiConfigMgrProxiErrorData.SetRamBlockStatus
        OpEventReadBlock_ReadBlock_PS_SWC_ProxiConfigMgrProxiConfigTable: start-on-event=ReadBlock, operation=PS_SWC_ProxiConfigMgrProxiConfigTable.ReadBlock
        OpEventReadBlock_ReadBlock_PS_SWC_ProxiConfigMgrProxiErrorData: start-on-event=ReadBlock, operation=PS_SWC_ProxiConfigMgrProxiErrorData.ReadBlock
        OpEventWriteBlock_WriteBlock_PS_SWC_ProxiConfigMgrProxiConfigTable: start-on-event=WriteBlock, operation=PS_SWC_ProxiConfigMgrProxiConfigTable.WriteBlock
        OpEventWriteBlock_WriteBlock_PS_SWC_ProxiConfigMgrProxiErrorData: start-on-event=WriteBlock, operation=PS_SWC_ProxiConfigMgrProxiErrorData.WriteBlock
        OpEventInvalidateNvBlock_InvalidateNvBlock_PS_SWC_ProxiConfigMgrProxiConfigTable: start-on-event=InvalidateNvBlock, operation=PS_SWC_ProxiConfigMgrProxiConfigTable.InvalidateNvBlock
        OpEventInvalidateNvBlock_InvalidateNvBlock_PS_SWC_ProxiConfigMgrProxiErrorData: start-on-event=InvalidateNvBlock, operation=PS_SWC_ProxiConfigMgrProxiErrorData.InvalidateNvBlock
        OpEventEraseBlock_EraseBlock_PS_SWC_ProxiConfigMgrProxiConfigTable: start-on-event=EraseBlock, operation=PS_SWC_ProxiConfigMgrProxiConfigTable.EraseBlock
        OpEventEraseBlock_EraseBlock_PS_SWC_ProxiConfigMgrProxiErrorData: start-on-event=EraseBlock, operation=PS_SWC_ProxiConfigMgrProxiErrorData.EraseBlock
        OpEventSetBlockProtection_SetBlockProtection_PAdmin_SWC_ProxiConfigMgrProxiConfigTable: start-on-event=SetBlockProtection, operation=PAdmin_SWC_ProxiConfigMgrProxiConfigTable.SetBlockProtection
        OpEventSetBlockProtection_SetBlockProtection_PAdmin_SWC_ProxiConfigMgrProxiErrorData: start-on-event=SetBlockProtection, operation=PAdmin_SWC_ProxiConfigMgrProxiErrorData.SetBlockProtection
        OpEventRestoreBlockDefaults_RestoreBlockDefaults_PS_SWC_ProxiConfigMgrProxiConfigTable: start-on-event=RestoreBlockDefaults, operation=PS_SWC_ProxiConfigMgrProxiConfigTable.RestoreBlockDefaults
        OpEventRestoreBlockDefaults_RestoreBlockDefaults_PS_SWC_ProxiConfigMgrProxiErrorData: start-on-event=RestoreBlockDefaults, operation=PS_SWC_ProxiConfigMgrProxiErrorData.RestoreBlockDefaults
        OpEventGetErrorStatus_GetErrorStatus_PS_SWC_PartNumMgrDID_FD31_EOLCodingState: start-on-event=GetErrorStatus, operation=PS_SWC_PartNumMgrDID_FD31_EOLCodingState.GetErrorStatus
        OpEventSetRamBlockStatus_SetRamBlockStatus_PS_SWC_PartNumMgrDID_FD31_EOLCodingState: start-on-event=SetRamBlockStatus, operation=PS_SWC_PartNumMgrDID_FD31_EOLCodingState.SetRamBlockStatus
        OpEventReadBlock_ReadBlock_PS_SWC_PartNumMgrDID_FD31_EOLCodingState: start-on-event=ReadBlock, operation=PS_SWC_PartNumMgrDID_FD31_EOLCodingState.ReadBlock
        OpEventWriteBlock_WriteBlock_PS_SWC_PartNumMgrDID_FD31_EOLCodingState: start-on-event=WriteBlock, operation=PS_SWC_PartNumMgrDID_FD31_EOLCodingState.WriteBlock
        OpEventInvalidateNvBlock_InvalidateNvBlock_PS_SWC_PartNumMgrDID_FD31_EOLCodingState: start-on-event=InvalidateNvBlock, operation=PS_SWC_PartNumMgrDID_FD31_EOLCodingState.InvalidateNvBlock
        OpEventEraseBlock_EraseBlock_PS_SWC_PartNumMgrDID_FD31_EOLCodingState: start-on-event=EraseBlock, operation=PS_SWC_PartNumMgrDID_FD31_EOLCodingState.EraseBlock
        OpEventSetBlockProtection_SetBlockProtection_PAdmin_SWC_PartNumMgrDID_FD31_EOLCodingState: start-on-event=SetBlockProtection, operation=PAdmin_SWC_PartNumMgrDID_FD31_EOLCodingState.SetBlockProtection
        OpEventRestoreBlockDefaults_RestoreBlockDefaults_PS_SWC_PartNumMgrDID_FD31_EOLCodingState: start-on-event=RestoreBlockDefaults, operation=PS_SWC_PartNumMgrDID_FD31_EOLCodingState.RestoreBlockDefaults
        OpEventGetErrorStatus_GetErrorStatus_PS_SWC_PartNumMgrDID_F110_Ecu_Diag_Info: start-on-event=GetErrorStatus, operation=PS_SWC_PartNumMgrDID_F110_Ecu_Diag_Info.GetErrorStatus
        OpEventGetErrorStatus_GetErrorStatus_PS_SWC_PartNumMgrDID_F132_EBOM_Ecu_PartNum: start-on-event=GetErrorStatus, operation=PS_SWC_PartNumMgrDID_F132_EBOM_Ecu_PartNum.GetErrorStatus
        OpEventGetErrorStatus_GetErrorStatus_PS_SWC_PartNumMgrDID_F133_EBOM_Asm_PartNum: start-on-event=GetErrorStatus, operation=PS_SWC_PartNumMgrDID_F133_EBOM_Asm_PartNum.GetErrorStatus
        OpEventGetErrorStatus_GetErrorStatus_PS_SWC_PartNumMgrDID_F134_CODEP_Asm_PartNum: start-on-event=GetErrorStatus, operation=PS_SWC_PartNumMgrDID_F134_CODEP_Asm_PartNum.GetErrorStatus
        OpEventGetErrorStatus_GetErrorStatus_PS_SWC_PartNumMgrDID_F180_Boot_SW_Ver_Info: start-on-event=GetErrorStatus, operation=PS_SWC_PartNumMgrDID_F180_Boot_SW_Ver_Info.GetErrorStatus
        OpEventGetErrorStatus_GetErrorStatus_PS_SWC_PartNumMgrDID_F187_CODEP_Ecu_PartNum: start-on-event=GetErrorStatus, operation=PS_SWC_PartNumMgrDID_F187_CODEP_Ecu_PartNum.GetErrorStatus
        OpEventGetErrorStatus_GetErrorStatus_PS_SWC_PartNumMgrDID_F188_FCA_ESLM_Ecu_SW_Num: start-on-event=GetErrorStatus, operation=PS_SWC_PartNumMgrDID_F188_FCA_ESLM_Ecu_SW_Num.GetErrorStatus
        OpEventGetErrorStatus_GetErrorStatus_PS_SWC_PartNumMgrDID_F18A_FCA_ESLM_Ecu_SW_Cal_Num: start-on-event=GetErrorStatus, operation=PS_SWC_PartNumMgrDID_F18A_FCA_ESLM_Ecu_SW_Cal_Num.GetErrorStatus
        OpEventGetErrorStatus_GetErrorStatus_PS_SWC_PartNumMgrDID_F18B_FCA_ESLM_ECU_SW_App_Num: start-on-event=GetErrorStatus, operation=PS_SWC_PartNumMgrDID_F18B_FCA_ESLM_ECU_SW_App_Num.GetErrorStatus
        OpEventGetErrorStatus_GetErrorStatus_PS_SWC_PartNumMgrDID_F194_Supplier_Ecu_SW_PartNum: start-on-event=GetErrorStatus, operation=PS_SWC_PartNumMgrDID_F194_Supplier_Ecu_SW_PartNum.GetErrorStatus
        OpEventGetErrorStatus_GetErrorStatus_PS_SWC_PartNumMgrDID_F195_Supplier_Ecu_SW_VerNum: start-on-event=GetErrorStatus, operation=PS_SWC_PartNumMgrDID_F195_Supplier_Ecu_SW_VerNum.GetErrorStatus
        OpEventSetRamBlockStatus_SetRamBlockStatus_PS_SWC_PartNumMgrDID_F110_Ecu_Diag_Info: start-on-event=SetRamBlockStatus, operation=PS_SWC_PartNumMgrDID_F110_Ecu_Diag_Info.SetRamBlockStatus
        OpEventSetRamBlockStatus_SetRamBlockStatus_PS_SWC_PartNumMgrDID_F132_EBOM_Ecu_PartNum: start-on-event=SetRamBlockStatus, operation=PS_SWC_PartNumMgrDID_F132_EBOM_Ecu_PartNum.SetRamBlockStatus
        OpEventSetRamBlockStatus_SetRamBlockStatus_PS_SWC_PartNumMgrDID_F133_EBOM_Asm_PartNum: start-on-event=SetRamBlockStatus, operation=PS_SWC_PartNumMgrDID_F133_EBOM_Asm_PartNum.SetRamBlockStatus
        OpEventSetRamBlockStatus_SetRamBlockStatus_PS_SWC_PartNumMgrDID_F134_CODEP_Asm_PartNum: start-on-event=SetRamBlockStatus, operation=PS_SWC_PartNumMgrDID_F134_CODEP_Asm_PartNum.SetRamBlockStatus
        OpEventSetRamBlockStatus_SetRamBlockStatus_PS_SWC_PartNumMgrDID_F180_Boot_SW_Ver_Info: start-on-event=SetRamBlockStatus, operation=PS_SWC_PartNumMgrDID_F180_Boot_SW_Ver_Info.SetRamBlockStatus
        OpEventSetRamBlockStatus_SetRamBlockStatus_PS_SWC_PartNumMgrDID_F187_CODEP_Ecu_PartNum: start-on-event=SetRamBlockStatus, operation=PS_SWC_PartNumMgrDID_F187_CODEP_Ecu_PartNum.SetRamBlockStatus
        OpEventSetRamBlockStatus_SetRamBlockStatus_PS_SWC_PartNumMgrDID_F188_FCA_ESLM_Ecu_SW_Num: start-on-event=SetRamBlockStatus, operation=PS_SWC_PartNumMgrDID_F188_FCA_ESLM_Ecu_SW_Num.SetRamBlockStatus
        OpEventSetRamBlockStatus_SetRamBlockStatus_PS_SWC_PartNumMgrDID_F18A_FCA_ESLM_Ecu_SW_Cal_Num: start-on-event=SetRamBlockStatus, operation=PS_SWC_PartNumMgrDID_F18A_FCA_ESLM_Ecu_SW_Cal_Num.SetRamBlockStatus
        OpEventSetRamBlockStatus_SetRamBlockStatus_PS_SWC_PartNumMgrDID_F18B_FCA_ESLM_ECU_SW_App_Num: start-on-event=SetRamBlockStatus, operation=PS_SWC_PartNumMgrDID_F18B_FCA_ESLM_ECU_SW_App_Num.SetRamBlockStatus
        OpEventSetRamBlockStatus_SetRamBlockStatus_PS_SWC_PartNumMgrDID_F194_Supplier_Ecu_SW_PartNum: start-on-event=SetRamBlockStatus, operation=PS_SWC_PartNumMgrDID_F194_Supplier_Ecu_SW_PartNum.SetRamBlockStatus
        OpEventSetRamBlockStatus_SetRamBlockStatus_PS_SWC_PartNumMgrDID_F195_Supplier_Ecu_SW_VerNum: start-on-event=SetRamBlockStatus, operation=PS_SWC_PartNumMgrDID_F195_Supplier_Ecu_SW_VerNum.SetRamBlockStatus
        OpEventReadBlock_ReadBlock_PS_SWC_PartNumMgrDID_F110_Ecu_Diag_Info: start-on-event=ReadBlock, operation=PS_SWC_PartNumMgrDID_F110_Ecu_Diag_Info.ReadBlock
        OpEventReadBlock_ReadBlock_PS_SWC_PartNumMgrDID_F132_EBOM_Ecu_PartNum: start-on-event=ReadBlock, operation=PS_SWC_PartNumMgrDID_F132_EBOM_Ecu_PartNum.ReadBlock
        OpEventReadBlock_ReadBlock_PS_SWC_PartNumMgrDID_F133_EBOM_Asm_PartNum: start-on-event=ReadBlock, operation=PS_SWC_PartNumMgrDID_F133_EBOM_Asm_PartNum.ReadBlock
        OpEventReadBlock_ReadBlock_PS_SWC_PartNumMgrDID_F134_CODEP_Asm_PartNum: start-on-event=ReadBlock, operation=PS_SWC_PartNumMgrDID_F134_CODEP_Asm_PartNum.ReadBlock
        OpEventReadBlock_ReadBlock_PS_SWC_PartNumMgrDID_F180_Boot_SW_Ver_Info: start-on-event=ReadBlock, operation=PS_SWC_PartNumMgrDID_F180_Boot_SW_Ver_Info.ReadBlock
        OpEventReadBlock_ReadBlock_PS_SWC_PartNumMgrDID_F187_CODEP_Ecu_PartNum: start-on-event=ReadBlock, operation=PS_SWC_PartNumMgrDID_F187_CODEP_Ecu_PartNum.ReadBlock
        OpEventReadBlock_ReadBlock_PS_SWC_PartNumMgrDID_F188_FCA_ESLM_Ecu_SW_Num: start-on-event=ReadBlock, operation=PS_SWC_PartNumMgrDID_F188_FCA_ESLM_Ecu_SW_Num.ReadBlock
        OpEventReadBlock_ReadBlock_PS_SWC_PartNumMgrDID_F18A_FCA_ESLM_Ecu_SW_Cal_Num: start-on-event=ReadBlock, operation=PS_SWC_PartNumMgrDID_F18A_FCA_ESLM_Ecu_SW_Cal_Num.ReadBlock
        OpEventReadBlock_ReadBlock_PS_SWC_PartNumMgrDID_F18B_FCA_ESLM_ECU_SW_App_Num: start-on-event=ReadBlock, operation=PS_SWC_PartNumMgrDID_F18B_FCA_ESLM_ECU_SW_App_Num.ReadBlock
        OpEventReadBlock_ReadBlock_PS_SWC_PartNumMgrDID_F194_Supplier_Ecu_SW_PartNum: start-on-event=ReadBlock, operation=PS_SWC_PartNumMgrDID_F194_Supplier_Ecu_SW_PartNum.ReadBlock
        OpEventReadBlock_ReadBlock_PS_SWC_PartNumMgrDID_F195_Supplier_Ecu_SW_VerNum: start-on-event=ReadBlock, operation=PS_SWC_PartNumMgrDID_F195_Supplier_Ecu_SW_VerNum.ReadBlock
        OpEventWriteBlock_WriteBlock_PS_SWC_PartNumMgrDID_F110_Ecu_Diag_Info: start-on-event=WriteBlock, operation=PS_SWC_PartNumMgrDID_F110_Ecu_Diag_Info.WriteBlock
        OpEventWriteBlock_WriteBlock_PS_SWC_PartNumMgrDID_F132_EBOM_Ecu_PartNum: start-on-event=WriteBlock, operation=PS_SWC_PartNumMgrDID_F132_EBOM_Ecu_PartNum.WriteBlock
        OpEventWriteBlock_WriteBlock_PS_SWC_PartNumMgrDID_F133_EBOM_Asm_PartNum: start-on-event=WriteBlock, operation=PS_SWC_PartNumMgrDID_F133_EBOM_Asm_PartNum.WriteBlock
        OpEventWriteBlock_WriteBlock_PS_SWC_PartNumMgrDID_F134_CODEP_Asm_PartNum: start-on-event=WriteBlock, operation=PS_SWC_PartNumMgrDID_F134_CODEP_Asm_PartNum.WriteBlock
        OpEventWriteBlock_WriteBlock_PS_SWC_PartNumMgrDID_F180_Boot_SW_Ver_Info: start-on-event=WriteBlock, operation=PS_SWC_PartNumMgrDID_F180_Boot_SW_Ver_Info.WriteBlock
        OpEventWriteBlock_WriteBlock_PS_SWC_PartNumMgrDID_F187_CODEP_Ecu_PartNum: start-on-event=WriteBlock, operation=PS_SWC_PartNumMgrDID_F187_CODEP_Ecu_PartNum.WriteBlock
        OpEventWriteBlock_WriteBlock_PS_SWC_PartNumMgrDID_F188_FCA_ESLM_Ecu_SW_Num: start-on-event=WriteBlock, operation=PS_SWC_PartNumMgrDID_F188_FCA_ESLM_Ecu_SW_Num.WriteBlock
        OpEventWriteBlock_WriteBlock_PS_SWC_PartNumMgrDID_F18A_FCA_ESLM_Ecu_SW_Cal_Num: start-on-event=WriteBlock, operation=PS_SWC_PartNumMgrDID_F18A_FCA_ESLM_Ecu_SW_Cal_Num.WriteBlock
        OpEventWriteBlock_WriteBlock_PS_SWC_PartNumMgrDID_F18B_FCA_ESLM_ECU_SW_App_Num: start-on-event=WriteBlock, operation=PS_SWC_PartNumMgrDID_F18B_FCA_ESLM_ECU_SW_App_Num.WriteBlock
        OpEventWriteBlock_WriteBlock_PS_SWC_PartNumMgrDID_F194_Supplier_Ecu_SW_PartNum: start-on-event=WriteBlock, operation=PS_SWC_PartNumMgrDID_F194_Supplier_Ecu_SW_PartNum.WriteBlock
        OpEventWriteBlock_WriteBlock_PS_SWC_PartNumMgrDID_F195_Supplier_Ecu_SW_VerNum: start-on-event=WriteBlock, operation=PS_SWC_PartNumMgrDID_F195_Supplier_Ecu_SW_VerNum.WriteBlock
        OpEventInvalidateNvBlock_InvalidateNvBlock_PS_SWC_PartNumMgrDID_F110_Ecu_Diag_Info: start-on-event=InvalidateNvBlock, operation=PS_SWC_PartNumMgrDID_F110_Ecu_Diag_Info.InvalidateNvBlock
        OpEventInvalidateNvBlock_InvalidateNvBlock_PS_SWC_PartNumMgrDID_F132_EBOM_Ecu_PartNum: start-on-event=InvalidateNvBlock, operation=PS_SWC_PartNumMgrDID_F132_EBOM_Ecu_PartNum.InvalidateNvBlock
        OpEventInvalidateNvBlock_InvalidateNvBlock_PS_SWC_PartNumMgrDID_F133_EBOM_Asm_PartNum: start-on-event=InvalidateNvBlock, operation=PS_SWC_PartNumMgrDID_F133_EBOM_Asm_PartNum.InvalidateNvBlock
        OpEventInvalidateNvBlock_InvalidateNvBlock_PS_SWC_PartNumMgrDID_F134_CODEP_Asm_PartNum: start-on-event=InvalidateNvBlock, operation=PS_SWC_PartNumMgrDID_F134_CODEP_Asm_PartNum.InvalidateNvBlock
        OpEventInvalidateNvBlock_InvalidateNvBlock_PS_SWC_PartNumMgrDID_F180_Boot_SW_Ver_Info: start-on-event=InvalidateNvBlock, operation=PS_SWC_PartNumMgrDID_F180_Boot_SW_Ver_Info.InvalidateNvBlock
        OpEventInvalidateNvBlock_InvalidateNvBlock_PS_SWC_PartNumMgrDID_F187_CODEP_Ecu_PartNum: start-on-event=InvalidateNvBlock, operation=PS_SWC_PartNumMgrDID_F187_CODEP_Ecu_PartNum.InvalidateNvBlock
        OpEventInvalidateNvBlock_InvalidateNvBlock_PS_SWC_PartNumMgrDID_F188_FCA_ESLM_Ecu_SW_Num: start-on-event=InvalidateNvBlock, operation=PS_SWC_PartNumMgrDID_F188_FCA_ESLM_Ecu_SW_Num.InvalidateNvBlock
        OpEventInvalidateNvBlock_InvalidateNvBlock_PS_SWC_PartNumMgrDID_F18A_FCA_ESLM_Ecu_SW_Cal_Num: start-on-event=InvalidateNvBlock, operation=PS_SWC_PartNumMgrDID_F18A_FCA_ESLM_Ecu_SW_Cal_Num.InvalidateNvBlock
        OpEventInvalidateNvBlock_InvalidateNvBlock_PS_SWC_PartNumMgrDID_F18B_FCA_ESLM_ECU_SW_App_Num: start-on-event=InvalidateNvBlock, operation=PS_SWC_PartNumMgrDID_F18B_FCA_ESLM_ECU_SW_App_Num.InvalidateNvBlock
        OpEventInvalidateNvBlock_InvalidateNvBlock_PS_SWC_PartNumMgrDID_F194_Supplier_Ecu_SW_PartNum: start-on-event=InvalidateNvBlock, operation=PS_SWC_PartNumMgrDID_F194_Supplier_Ecu_SW_PartNum.InvalidateNvBlock
        OpEventInvalidateNvBlock_InvalidateNvBlock_PS_SWC_PartNumMgrDID_F195_Supplier_Ecu_SW_VerNum: start-on-event=InvalidateNvBlock, operation=PS_SWC_PartNumMgrDID_F195_Supplier_Ecu_SW_VerNum.InvalidateNvBlock
        OpEventEraseBlock_EraseBlock_PS_SWC_PartNumMgrDID_F110_Ecu_Diag_Info: start-on-event=EraseBlock, operation=PS_SWC_PartNumMgrDID_F110_Ecu_Diag_Info.EraseBlock
        OpEventEraseBlock_EraseBlock_PS_SWC_PartNumMgrDID_F132_EBOM_Ecu_PartNum: start-on-event=EraseBlock, operation=PS_SWC_PartNumMgrDID_F132_EBOM_Ecu_PartNum.EraseBlock
        OpEventEraseBlock_EraseBlock_PS_SWC_PartNumMgrDID_F133_EBOM_Asm_PartNum: start-on-event=EraseBlock, operation=PS_SWC_PartNumMgrDID_F133_EBOM_Asm_PartNum.EraseBlock
        OpEventEraseBlock_EraseBlock_PS_SWC_PartNumMgrDID_F134_CODEP_Asm_PartNum: start-on-event=EraseBlock, operation=PS_SWC_PartNumMgrDID_F134_CODEP_Asm_PartNum.EraseBlock
        OpEventEraseBlock_EraseBlock_PS_SWC_PartNumMgrDID_F180_Boot_SW_Ver_Info: start-on-event=EraseBlock, operation=PS_SWC_PartNumMgrDID_F180_Boot_SW_Ver_Info.EraseBlock
        OpEventEraseBlock_EraseBlock_PS_SWC_PartNumMgrDID_F187_CODEP_Ecu_PartNum: start-on-event=EraseBlock, operation=PS_SWC_PartNumMgrDID_F187_CODEP_Ecu_PartNum.EraseBlock
        OpEventEraseBlock_EraseBlock_PS_SWC_PartNumMgrDID_F188_FCA_ESLM_Ecu_SW_Num: start-on-event=EraseBlock, operation=PS_SWC_PartNumMgrDID_F188_FCA_ESLM_Ecu_SW_Num.EraseBlock
        OpEventEraseBlock_EraseBlock_PS_SWC_PartNumMgrDID_F18A_FCA_ESLM_Ecu_SW_Cal_Num: start-on-event=EraseBlock, operation=PS_SWC_PartNumMgrDID_F18A_FCA_ESLM_Ecu_SW_Cal_Num.EraseBlock
        OpEventEraseBlock_EraseBlock_PS_SWC_PartNumMgrDID_F18B_FCA_ESLM_ECU_SW_App_Num: start-on-event=EraseBlock, operation=PS_SWC_PartNumMgrDID_F18B_FCA_ESLM_ECU_SW_App_Num.EraseBlock
        OpEventEraseBlock_EraseBlock_PS_SWC_PartNumMgrDID_F194_Supplier_Ecu_SW_PartNum: start-on-event=EraseBlock, operation=PS_SWC_PartNumMgrDID_F194_Supplier_Ecu_SW_PartNum.EraseBlock
        OpEventEraseBlock_EraseBlock_PS_SWC_PartNumMgrDID_F195_Supplier_Ecu_SW_VerNum: start-on-event=EraseBlock, operation=PS_SWC_PartNumMgrDID_F195_Supplier_Ecu_SW_VerNum.EraseBlock
        OpEventSetBlockProtection_SetBlockProtection_PAdmin_SWC_PartNumMgrDID_F110_Ecu_Diag_Info: start-on-event=SetBlockProtection, operation=PAdmin_SWC_PartNumMgrDID_F110_Ecu_Diag_Info.SetBlockProtection
        OpEventSetBlockProtection_SetBlockProtection_PAdmin_SWC_PartNumMgrDID_F132_EBOM_Ecu_PartNum: start-on-event=SetBlockProtection, operation=PAdmin_SWC_PartNumMgrDID_F132_EBOM_Ecu_PartNum.SetBlockProtection
        OpEventSetBlockProtection_SetBlockProtection_PAdmin_SWC_PartNumMgrDID_F133_EBOM_Asm_PartNum: start-on-event=SetBlockProtection, operation=PAdmin_SWC_PartNumMgrDID_F133_EBOM_Asm_PartNum.SetBlockProtection
        OpEventSetBlockProtection_SetBlockProtection_PAdmin_SWC_PartNumMgrDID_F134_CODEP_Asm_PartNum: start-on-event=SetBlockProtection, operation=PAdmin_SWC_PartNumMgrDID_F134_CODEP_Asm_PartNum.SetBlockProtection
        OpEventSetBlockProtection_SetBlockProtection_PAdmin_SWC_PartNumMgrDID_F180_Boot_SW_Ver_Info: start-on-event=SetBlockProtection, operation=PAdmin_SWC_PartNumMgrDID_F180_Boot_SW_Ver_Info.SetBlockProtection
        OpEventSetBlockProtection_SetBlockProtection_PAdmin_SWC_PartNumMgrDID_F187_CODEP_Ecu_PartNum: start-on-event=SetBlockProtection, operation=PAdmin_SWC_PartNumMgrDID_F187_CODEP_Ecu_PartNum.SetBlockProtection
        OpEventSetBlockProtection_SetBlockProtection_PAdmin_SWC_PartNumMgrDID_F188_FCA_ESLM_Ecu_SW_Num: start-on-event=SetBlockProtection, operation=PAdmin_SWC_PartNumMgrDID_F188_FCA_ESLM_Ecu_SW_Num.SetBlockProtection
        OpEventSetBlockProtection_SetBlockProtection_PAdmin_SWC_PartNumMgrDID_F18A_FCA_ESLM_Ecu_SW_Cal_Num: start-on-event=SetBlockProtection, operation=PAdmin_SWC_PartNumMgrDID_F18A_FCA_ESLM_Ecu_SW_Cal_Num.SetBlockProtection
        OpEventSetBlockProtection_SetBlockProtection_PAdmin_SWC_PartNumMgrDID_F18B_FCA_ESLM_ECU_SW_App_Num: start-on-event=SetBlockProtection, operation=PAdmin_SWC_PartNumMgrDID_F18B_FCA_ESLM_ECU_SW_App_Num.SetBlockProtection
        OpEventSetBlockProtection_SetBlockProtection_PAdmin_SWC_PartNumMgrDID_F194_Supplier_Ecu_SW_PartNum: start-on-event=SetBlockProtection, operation=PAdmin_SWC_PartNumMgrDID_F194_Supplier_Ecu_SW_PartNum.SetBlockProtection
        OpEventSetBlockProtection_SetBlockProtection_PAdmin_SWC_PartNumMgrDID_F195_Supplier_Ecu_SW_VerNum: start-on-event=SetBlockProtection, operation=PAdmin_SWC_PartNumMgrDID_F195_Supplier_Ecu_SW_VerNum.SetBlockProtection
        OpEventRestoreBlockDefaults_RestoreBlockDefaults_PS_SWC_PartNumMgrDID_F110_Ecu_Diag_Info: start-on-event=RestoreBlockDefaults, operation=PS_SWC_PartNumMgrDID_F110_Ecu_Diag_Info.RestoreBlockDefaults
        OpEventRestoreBlockDefaults_RestoreBlockDefaults_PS_SWC_PartNumMgrDID_F132_EBOM_Ecu_PartNum: start-on-event=RestoreBlockDefaults, operation=PS_SWC_PartNumMgrDID_F132_EBOM_Ecu_PartNum.RestoreBlockDefaults
        OpEventRestoreBlockDefaults_RestoreBlockDefaults_PS_SWC_PartNumMgrDID_F133_EBOM_Asm_PartNum: start-on-event=RestoreBlockDefaults, operation=PS_SWC_PartNumMgrDID_F133_EBOM_Asm_PartNum.RestoreBlockDefaults
        OpEventRestoreBlockDefaults_RestoreBlockDefaults_PS_SWC_PartNumMgrDID_F134_CODEP_Asm_PartNum: start-on-event=RestoreBlockDefaults, operation=PS_SWC_PartNumMgrDID_F134_CODEP_Asm_PartNum.RestoreBlockDefaults
        OpEventRestoreBlockDefaults_RestoreBlockDefaults_PS_SWC_PartNumMgrDID_F180_Boot_SW_Ver_Info: start-on-event=RestoreBlockDefaults, operation=PS_SWC_PartNumMgrDID_F180_Boot_SW_Ver_Info.RestoreBlockDefaults
        OpEventRestoreBlockDefaults_RestoreBlockDefaults_PS_SWC_PartNumMgrDID_F187_CODEP_Ecu_PartNum: start-on-event=RestoreBlockDefaults, operation=PS_SWC_PartNumMgrDID_F187_CODEP_Ecu_PartNum.RestoreBlockDefaults
        OpEventRestoreBlockDefaults_RestoreBlockDefaults_PS_SWC_PartNumMgrDID_F18A_FCA_ESLM_Ecu_SW_Cal_Num: start-on-event=RestoreBlockDefaults, operation=PS_SWC_PartNumMgrDID_F18A_FCA_ESLM_Ecu_SW_Cal_Num.RestoreBlockDefaults
        OpEventRestoreBlockDefaults_RestoreBlockDefaults_PS_SWC_PartNumMgrDID_F18B_FCA_ESLM_ECU_SW_App_Num: start-on-event=RestoreBlockDefaults, operation=PS_SWC_PartNumMgrDID_F18B_FCA_ESLM_ECU_SW_App_Num.RestoreBlockDefaults
        OpEventRestoreBlockDefaults_RestoreBlockDefaults_PS_SWC_PartNumMgrDID_F194_Supplier_Ecu_SW_PartNum: start-on-event=RestoreBlockDefaults, operation=PS_SWC_PartNumMgrDID_F194_Supplier_Ecu_SW_PartNum.RestoreBlockDefaults
        OpEventRestoreBlockDefaults_RestoreBlockDefaults_PS_SWC_PartNumMgrDID_F195_Supplier_Ecu_SW_VerNum: start-on-event=RestoreBlockDefaults, operation=PS_SWC_PartNumMgrDID_F195_Supplier_Ecu_SW_VerNum.RestoreBlockDefaults
        OpEventRestoreBlockDefaults_RestoreBlockDefaults_PS_SWC_PartNumMgrDID_F188_FCA_ESLM_Ecu_SW_Num: start-on-event=RestoreBlockDefaults, operation=PS_SWC_PartNumMgrDID_F188_FCA_ESLM_Ecu_SW_Num.RestoreBlockDefaults
        OpEventGetErrorStatus_GetErrorStatus_PS_CalDataProviderSVSCamCurrentCalibData: start-on-event=GetErrorStatus, operation=PS_CalDataProviderSVSCamCurrentCalibData.GetErrorStatus
        OpEventGetErrorStatus_GetErrorStatus_PS_CalDataProviderSVSCamEOLCalibData: start-on-event=GetErrorStatus, operation=PS_CalDataProviderSVSCamEOLCalibData.GetErrorStatus
        OpEventGetErrorStatus_GetErrorStatus_PS_CalDataProviderSVSCamOCCalibData: start-on-event=GetErrorStatus, operation=PS_CalDataProviderSVSCamOCCalibData.GetErrorStatus
        OpEventGetErrorStatus_GetErrorStatus_PS_CalDataProviderSVSCamSCCalibData: start-on-event=GetErrorStatus, operation=PS_CalDataProviderSVSCamSCCalibData.GetErrorStatus
        OpEventSetRamBlockStatus_SetRamBlockStatus_PS_CalDataProviderSVSCamCurrentCalibData: start-on-event=SetRamBlockStatus, operation=PS_CalDataProviderSVSCamCurrentCalibData.SetRamBlockStatus
        OpEventSetRamBlockStatus_SetRamBlockStatus_PS_CalDataProviderSVSCamEOLCalibData: start-on-event=SetRamBlockStatus, operation=PS_CalDataProviderSVSCamEOLCalibData.SetRamBlockStatus
        OpEventSetRamBlockStatus_SetRamBlockStatus_PS_CalDataProviderSVSCamOCCalibData: start-on-event=SetRamBlockStatus, operation=PS_CalDataProviderSVSCamOCCalibData.SetRamBlockStatus
        OpEventSetRamBlockStatus_SetRamBlockStatus_PS_CalDataProviderSVSCamSCCalibData: start-on-event=SetRamBlockStatus, operation=PS_CalDataProviderSVSCamSCCalibData.SetRamBlockStatus
        OpEventReadBlock_ReadBlock_PS_CalDataProviderSVSCamCurrentCalibData: start-on-event=ReadBlock, operation=PS_CalDataProviderSVSCamCurrentCalibData.ReadBlock
        OpEventReadBlock_ReadBlock_PS_CalDataProviderSVSCamEOLCalibData: start-on-event=ReadBlock, operation=PS_CalDataProviderSVSCamEOLCalibData.ReadBlock
        OpEventReadBlock_ReadBlock_PS_CalDataProviderSVSCamOCCalibData: start-on-event=ReadBlock, operation=PS_CalDataProviderSVSCamOCCalibData.ReadBlock
        OpEventReadBlock_ReadBlock_PS_CalDataProviderSVSCamSCCalibData: start-on-event=ReadBlock, operation=PS_CalDataProviderSVSCamSCCalibData.ReadBlock
        OpEventWriteBlock_WriteBlock_PS_CalDataProviderSVSCamCurrentCalibData: start-on-event=WriteBlock, operation=PS_CalDataProviderSVSCamCurrentCalibData.WriteBlock
        OpEventWriteBlock_WriteBlock_PS_CalDataProviderSVSCamEOLCalibData: start-on-event=WriteBlock, operation=PS_CalDataProviderSVSCamEOLCalibData.WriteBlock
        OpEventWriteBlock_WriteBlock_PS_CalDataProviderSVSCamOCCalibData: start-on-event=WriteBlock, operation=PS_CalDataProviderSVSCamOCCalibData.WriteBlock
        OpEventWriteBlock_WriteBlock_PS_CalDataProviderSVSCamSCCalibData: start-on-event=WriteBlock, operation=PS_CalDataProviderSVSCamSCCalibData.WriteBlock
        OpEventInvalidateNvBlock_InvalidateNvBlock_PS_CalDataProviderSVSCamCurrentCalibData: start-on-event=InvalidateNvBlock, operation=PS_CalDataProviderSVSCamCurrentCalibData.InvalidateNvBlock
        OpEventInvalidateNvBlock_InvalidateNvBlock_PS_CalDataProviderSVSCamEOLCalibData: start-on-event=InvalidateNvBlock, operation=PS_CalDataProviderSVSCamEOLCalibData.InvalidateNvBlock
        OpEventInvalidateNvBlock_InvalidateNvBlock_PS_CalDataProviderSVSCamOCCalibData: start-on-event=InvalidateNvBlock, operation=PS_CalDataProviderSVSCamOCCalibData.InvalidateNvBlock
        OpEventInvalidateNvBlock_InvalidateNvBlock_PS_CalDataProviderSVSCamSCCalibData: start-on-event=InvalidateNvBlock, operation=PS_CalDataProviderSVSCamSCCalibData.InvalidateNvBlock
        OpEventEraseBlock_EraseBlock_PS_CalDataProviderSVSCamCurrentCalibData: start-on-event=EraseBlock, operation=PS_CalDataProviderSVSCamCurrentCalibData.EraseBlock
        OpEventEraseBlock_EraseBlock_PS_CalDataProviderSVSCamEOLCalibData: start-on-event=EraseBlock, operation=PS_CalDataProviderSVSCamEOLCalibData.EraseBlock
        OpEventEraseBlock_EraseBlock_PS_CalDataProviderSVSCamOCCalibData: start-on-event=EraseBlock, operation=PS_CalDataProviderSVSCamOCCalibData.EraseBlock
        OpEventEraseBlock_EraseBlock_PS_CalDataProviderSVSCamSCCalibData: start-on-event=EraseBlock, operation=PS_CalDataProviderSVSCamSCCalibData.EraseBlock
        OpEventSetBlockProtection_SetBlockProtection_PAdmin_CalDataProviderSVSCamCurrentCalibData: start-on-event=SetBlockProtection, operation=PAdmin_CalDataProviderSVSCamCurrentCalibData.SetBlockProtection
        OpEventSetBlockProtection_SetBlockProtection_PAdmin_CalDataProviderSVSCamEOLCalibData: start-on-event=SetBlockProtection, operation=PAdmin_CalDataProviderSVSCamEOLCalibData.SetBlockProtection
        OpEventSetBlockProtection_SetBlockProtection_PAdmin_CalDataProviderSVSCamOCCalibData: start-on-event=SetBlockProtection, operation=PAdmin_CalDataProviderSVSCamOCCalibData.SetBlockProtection
        OpEventSetBlockProtection_SetBlockProtection_PAdmin_CalDataProviderSVSCamSCCalibData: start-on-event=SetBlockProtection, operation=PAdmin_CalDataProviderSVSCamSCCalibData.SetBlockProtection
        OpEventRestoreBlockDefaults_RestoreBlockDefaults_PS_CalDataProviderSVSCamCurrentCalibData: start-on-event=RestoreBlockDefaults, operation=PS_CalDataProviderSVSCamCurrentCalibData.RestoreBlockDefaults
        OpEventRestoreBlockDefaults_RestoreBlockDefaults_PS_CalDataProviderSVSCamEOLCalibData: start-on-event=RestoreBlockDefaults, operation=PS_CalDataProviderSVSCamEOLCalibData.RestoreBlockDefaults
        OpEventRestoreBlockDefaults_RestoreBlockDefaults_PS_CalDataProviderSVSCamOCCalibData: start-on-event=RestoreBlockDefaults, operation=PS_CalDataProviderSVSCamOCCalibData.RestoreBlockDefaults
        OpEventRestoreBlockDefaults_RestoreBlockDefaults_PS_CalDataProviderSVSCamSCCalibData: start-on-event=RestoreBlockDefaults, operation=PS_CalDataProviderSVSCamSCCalibData.RestoreBlockDefaults
        OpEventGetErrorStatus_GetErrorStatus_PS_SWC_PartNumMgrUssSensorMarrData: start-on-event=GetErrorStatus, operation=PS_SWC_PartNumMgrUssSensorMarrData.GetErrorStatus
        OpEventSetRamBlockStatus_SetRamBlockStatus_PS_SWC_PartNumMgrUssSensorMarrData: start-on-event=SetRamBlockStatus, operation=PS_SWC_PartNumMgrUssSensorMarrData.SetRamBlockStatus
        OpEventReadBlock_ReadBlock_PS_SWC_PartNumMgrUssSensorMarrData: start-on-event=ReadBlock, operation=PS_SWC_PartNumMgrUssSensorMarrData.ReadBlock
        OpEventWriteBlock_WriteBlock_PS_SWC_PartNumMgrUssSensorMarrData: start-on-event=WriteBlock, operation=PS_SWC_PartNumMgrUssSensorMarrData.WriteBlock
        OpEventInvalidateNvBlock_InvalidateNvBlock_PS_SWC_PartNumMgrUssSensorMarrData: start-on-event=InvalidateNvBlock, operation=PS_SWC_PartNumMgrUssSensorMarrData.InvalidateNvBlock
        OpEventEraseBlock_EraseBlock_PS_SWC_PartNumMgrUssSensorMarrData: start-on-event=EraseBlock, operation=PS_SWC_PartNumMgrUssSensorMarrData.EraseBlock
        OpEventSetBlockProtection_SetBlockProtection_PAdmin_SWC_PartNumMgrUssSensorMarrData: start-on-event=SetBlockProtection, operation=PAdmin_SWC_PartNumMgrUssSensorMarrData.SetBlockProtection
        OpEventRestoreBlockDefaults_RestoreBlockDefaults_PS_SWC_PartNumMgrUssSensorMarrData: start-on-event=RestoreBlockDefaults, operation=PS_SWC_PartNumMgrUssSensorMarrData.RestoreBlockDefaults
        OpEventGetErrorStatus_GetErrorStatus_PS_SWC_DIDMgrDID_FD01_PrevCalibDataCopy: start-on-event=GetErrorStatus, operation=PS_SWC_DIDMgrDID_FD01_PrevCalibDataCopy.GetErrorStatus
        OpEventSetRamBlockStatus_SetRamBlockStatus_PS_SWC_DIDMgrDID_FD01_PrevCalibDataCopy: start-on-event=SetRamBlockStatus, operation=PS_SWC_DIDMgrDID_FD01_PrevCalibDataCopy.SetRamBlockStatus
        OpEventReadBlock_ReadBlock_PS_SWC_DIDMgrDID_FD01_PrevCalibDataCopy: start-on-event=ReadBlock, operation=PS_SWC_DIDMgrDID_FD01_PrevCalibDataCopy.ReadBlock
        OpEventWriteBlock_WriteBlock_PS_SWC_DIDMgrDID_FD01_PrevCalibDataCopy: start-on-event=WriteBlock, operation=PS_SWC_DIDMgrDID_FD01_PrevCalibDataCopy.WriteBlock
        OpEventInvalidateNvBlock_InvalidateNvBlock_PS_SWC_DIDMgrDID_FD01_PrevCalibDataCopy: start-on-event=InvalidateNvBlock, operation=PS_SWC_DIDMgrDID_FD01_PrevCalibDataCopy.InvalidateNvBlock
        OpEventEraseBlock_EraseBlock_PS_SWC_DIDMgrDID_FD01_PrevCalibDataCopy: start-on-event=EraseBlock, operation=PS_SWC_DIDMgrDID_FD01_PrevCalibDataCopy.EraseBlock
        OpEventSetBlockProtection_SetBlockProtection_PAdmin_SWC_DIDMgrDID_FD01_PrevCalibDataCopy: start-on-event=SetBlockProtection, operation=PAdmin_SWC_DIDMgrDID_FD01_PrevCalibDataCopy.SetBlockProtection
        OpEventRestoreBlockDefaults_RestoreBlockDefaults_PS_SWC_DIDMgrDID_FD01_PrevCalibDataCopy: start-on-event=RestoreBlockDefaults, operation=PS_SWC_DIDMgrDID_FD01_PrevCalibDataCopy.RestoreBlockDefaults
        OpEventGetErrorStatus_GetErrorStatus_PS_SWC_DIDMgrDID_FD42_FailsafeDebug: start-on-event=GetErrorStatus, operation=PS_SWC_DIDMgrDID_FD42_FailsafeDebug.GetErrorStatus
        OpEventSetRamBlockStatus_SetRamBlockStatus_PS_SWC_DIDMgrDID_FD42_FailsafeDebug: start-on-event=SetRamBlockStatus, operation=PS_SWC_DIDMgrDID_FD42_FailsafeDebug.SetRamBlockStatus
        OpEventReadBlock_ReadBlock_PS_SWC_DIDMgrDID_FD42_FailsafeDebug: start-on-event=ReadBlock, operation=PS_SWC_DIDMgrDID_FD42_FailsafeDebug.ReadBlock
        OpEventWriteBlock_WriteBlock_PS_SWC_DIDMgrDID_FD42_FailsafeDebug: start-on-event=WriteBlock, operation=PS_SWC_DIDMgrDID_FD42_FailsafeDebug.WriteBlock
        OpEventInvalidateNvBlock_InvalidateNvBlock_PS_SWC_DIDMgrDID_FD42_FailsafeDebug: start-on-event=InvalidateNvBlock, operation=PS_SWC_DIDMgrDID_FD42_FailsafeDebug.InvalidateNvBlock
        OpEventEraseBlock_EraseBlock_PS_SWC_DIDMgrDID_FD42_FailsafeDebug: start-on-event=EraseBlock, operation=PS_SWC_DIDMgrDID_FD42_FailsafeDebug.EraseBlock
        OpEventSetBlockProtection_SetBlockProtection_PAdmin_SWC_DIDMgrDID_FD42_FailsafeDebug: start-on-event=SetBlockProtection, operation=PAdmin_SWC_DIDMgrDID_FD42_FailsafeDebug.SetBlockProtection
        OpEventRestoreBlockDefaults_RestoreBlockDefaults_PS_SWC_DIDMgrDID_FD42_FailsafeDebug: start-on-event=RestoreBlockDefaults, operation=PS_SWC_DIDMgrDID_FD42_FailsafeDebug.RestoreBlockDefaults
        OpEventGetErrorStatus_GetErrorStatus_PS_SWC_DIDMgrDID_RearBrakeEvent: start-on-event=GetErrorStatus, operation=PS_SWC_DIDMgrDID_RearBrakeEvent.GetErrorStatus
        OpEventSetRamBlockStatus_SetRamBlockStatus_PS_SWC_DIDMgrDID_RearBrakeEvent: start-on-event=SetRamBlockStatus, operation=PS_SWC_DIDMgrDID_RearBrakeEvent.SetRamBlockStatus
        OpEventReadBlock_ReadBlock_PS_SWC_DIDMgrDID_RearBrakeEvent: start-on-event=ReadBlock, operation=PS_SWC_DIDMgrDID_RearBrakeEvent.ReadBlock
        OpEventWriteBlock_WriteBlock_PS_SWC_DIDMgrDID_RearBrakeEvent: start-on-event=WriteBlock, operation=PS_SWC_DIDMgrDID_RearBrakeEvent.WriteBlock
        OpEventInvalidateNvBlock_InvalidateNvBlock_PS_SWC_DIDMgrDID_RearBrakeEvent: start-on-event=InvalidateNvBlock, operation=PS_SWC_DIDMgrDID_RearBrakeEvent.InvalidateNvBlock
        OpEventEraseBlock_EraseBlock_PS_SWC_DIDMgrDID_RearBrakeEvent: start-on-event=EraseBlock, operation=PS_SWC_DIDMgrDID_RearBrakeEvent.EraseBlock
        OpEventSetBlockProtection_SetBlockProtection_PAdmin_SWC_DIDMgrDID_RearBrakeEvent: start-on-event=SetBlockProtection, operation=PAdmin_SWC_DIDMgrDID_RearBrakeEvent.SetBlockProtection
        OpEventRestoreBlockDefaults_RestoreBlockDefaults_PS_SWC_DIDMgrDID_RearBrakeEvent: start-on-event=RestoreBlockDefaults, operation=PS_SWC_DIDMgrDID_RearBrakeEvent.RestoreBlockDefaults
        OpEventGetErrorStatus_GetErrorStatus_PS_SWC_DIDMgrDID_SPMAbrtEvent: start-on-event=GetErrorStatus, operation=PS_SWC_DIDMgrDID_SPMAbrtEvent.GetErrorStatus
        OpEventSetRamBlockStatus_SetRamBlockStatus_PS_SWC_DIDMgrDID_SPMAbrtEvent: start-on-event=SetRamBlockStatus, operation=PS_SWC_DIDMgrDID_SPMAbrtEvent.SetRamBlockStatus
        OpEventReadBlock_ReadBlock_PS_SWC_DIDMgrDID_SPMAbrtEvent: start-on-event=ReadBlock, operation=PS_SWC_DIDMgrDID_SPMAbrtEvent.ReadBlock
        OpEventWriteBlock_WriteBlock_PS_SWC_DIDMgrDID_SPMAbrtEvent: start-on-event=WriteBlock, operation=PS_SWC_DIDMgrDID_SPMAbrtEvent.WriteBlock
        OpEventInvalidateNvBlock_InvalidateNvBlock_PS_SWC_DIDMgrDID_SPMAbrtEvent: start-on-event=InvalidateNvBlock, operation=PS_SWC_DIDMgrDID_SPMAbrtEvent.InvalidateNvBlock
        OpEventEraseBlock_EraseBlock_PS_SWC_DIDMgrDID_SPMAbrtEvent: start-on-event=EraseBlock, operation=PS_SWC_DIDMgrDID_SPMAbrtEvent.EraseBlock
        OpEventSetBlockProtection_SetBlockProtection_PAdmin_SWC_DIDMgrDID_SPMAbrtEvent: start-on-event=SetBlockProtection, operation=PAdmin_SWC_DIDMgrDID_SPMAbrtEvent.SetBlockProtection
        OpEventRestoreBlockDefaults_RestoreBlockDefaults_PS_SWC_DIDMgrDID_SPMAbrtEvent: start-on-event=RestoreBlockDefaults, operation=PS_SWC_DIDMgrDID_SPMAbrtEvent.RestoreBlockDefaults
        OpEventGetErrorStatus_GetErrorStatus_PS_CDD_IPCHandlerFeatureAP_HMI_NvMData: start-on-event=GetErrorStatus, operation=PS_CDD_IPCHandlerFeatureAP_HMI_NvMData.GetErrorStatus
        OpEventSetRamBlockStatus_SetRamBlockStatus_PS_CDD_IPCHandlerFeatureAP_HMI_NvMData: start-on-event=SetRamBlockStatus, operation=PS_CDD_IPCHandlerFeatureAP_HMI_NvMData.SetRamBlockStatus
        OpEventReadBlock_ReadBlock_PS_CDD_IPCHandlerFeatureAP_HMI_NvMData: start-on-event=ReadBlock, operation=PS_CDD_IPCHandlerFeatureAP_HMI_NvMData.ReadBlock
        OpEventWriteBlock_WriteBlock_PS_CDD_IPCHandlerFeatureAP_HMI_NvMData: start-on-event=WriteBlock, operation=PS_CDD_IPCHandlerFeatureAP_HMI_NvMData.WriteBlock
        OpEventInvalidateNvBlock_InvalidateNvBlock_PS_CDD_IPCHandlerFeatureAP_HMI_NvMData: start-on-event=InvalidateNvBlock, operation=PS_CDD_IPCHandlerFeatureAP_HMI_NvMData.InvalidateNvBlock
        OpEventEraseBlock_EraseBlock_PS_CDD_IPCHandlerFeatureAP_HMI_NvMData: start-on-event=EraseBlock, operation=PS_CDD_IPCHandlerFeatureAP_HMI_NvMData.EraseBlock
        OpEventSetBlockProtection_SetBlockProtection_PAdmin_CDD_IPCHandlerFeatureAP_HMI_NvMData: start-on-event=SetBlockProtection, operation=PAdmin_CDD_IPCHandlerFeatureAP_HMI_NvMData.SetBlockProtection
        OpEventRestoreBlockDefaults_RestoreBlockDefaults_PS_CDD_IPCHandlerFeatureAP_HMI_NvMData: start-on-event=RestoreBlockDefaults, operation=PS_CDD_IPCHandlerFeatureAP_HMI_NvMData.RestoreBlockDefaults
        OpEventGetErrorStatus_GetErrorStatus_PS_SWC_DIDMgrDID_FD86_FunctionalSettings: start-on-event=GetErrorStatus, operation=PS_SWC_DIDMgrDID_FD86_FunctionalSettings.GetErrorStatus
        OpEventSetRamBlockStatus_SetRamBlockStatus_PS_SWC_DIDMgrDID_FD86_FunctionalSettings: start-on-event=SetRamBlockStatus, operation=PS_SWC_DIDMgrDID_FD86_FunctionalSettings.SetRamBlockStatus
        OpEventReadBlock_ReadBlock_PS_SWC_DIDMgrDID_FD86_FunctionalSettings: start-on-event=ReadBlock, operation=PS_SWC_DIDMgrDID_FD86_FunctionalSettings.ReadBlock
        OpEventWriteBlock_WriteBlock_PS_SWC_DIDMgrDID_FD86_FunctionalSettings: start-on-event=WriteBlock, operation=PS_SWC_DIDMgrDID_FD86_FunctionalSettings.WriteBlock
        OpEventInvalidateNvBlock_InvalidateNvBlock_PS_SWC_DIDMgrDID_FD86_FunctionalSettings: start-on-event=InvalidateNvBlock, operation=PS_SWC_DIDMgrDID_FD86_FunctionalSettings.InvalidateNvBlock
        OpEventEraseBlock_EraseBlock_PS_SWC_DIDMgrDID_FD86_FunctionalSettings: start-on-event=EraseBlock, operation=PS_SWC_DIDMgrDID_FD86_FunctionalSettings.EraseBlock
        OpEventSetBlockProtection_SetBlockProtection_PAdmin_SWC_DIDMgrDID_FD86_FunctionalSettings: start-on-event=SetBlockProtection, operation=PAdmin_SWC_DIDMgrDID_FD86_FunctionalSettings.SetBlockProtection
        OpEventRestoreBlockDefaults_RestoreBlockDefaults_PS_SWC_DIDMgrDID_FD86_FunctionalSettings: start-on-event=RestoreBlockDefaults, operation=PS_SWC_DIDMgrDID_FD86_FunctionalSettings.RestoreBlockDefaults
        OpEventGetErrorStatus_GetErrorStatus_PS_SWC_DIDMgrDID_2939_WakeupReason: start-on-event=GetErrorStatus, operation=PS_SWC_DIDMgrDID_2939_WakeupReason.GetErrorStatus
        OpEventGetErrorStatus_GetErrorStatus_PS_SWC_DIDMgrDID_FDF0_SleepProcess: start-on-event=GetErrorStatus, operation=PS_SWC_DIDMgrDID_FDF0_SleepProcess.GetErrorStatus
        OpEventSetRamBlockStatus_SetRamBlockStatus_PS_SWC_DIDMgrDID_2939_WakeupReason: start-on-event=SetRamBlockStatus, operation=PS_SWC_DIDMgrDID_2939_WakeupReason.SetRamBlockStatus
        OpEventSetRamBlockStatus_SetRamBlockStatus_PS_SWC_DIDMgrDID_FDF0_SleepProcess: start-on-event=SetRamBlockStatus, operation=PS_SWC_DIDMgrDID_FDF0_SleepProcess.SetRamBlockStatus
        OpEventReadBlock_ReadBlock_PS_SWC_DIDMgrDID_2939_WakeupReason: start-on-event=ReadBlock, operation=PS_SWC_DIDMgrDID_2939_WakeupReason.ReadBlock
        OpEventReadBlock_ReadBlock_PS_SWC_DIDMgrDID_FDF0_SleepProcess: start-on-event=ReadBlock, operation=PS_SWC_DIDMgrDID_FDF0_SleepProcess.ReadBlock
        OpEventWriteBlock_WriteBlock_PS_SWC_DIDMgrDID_2939_WakeupReason: start-on-event=WriteBlock, operation=PS_SWC_DIDMgrDID_2939_WakeupReason.WriteBlock
        OpEventWriteBlock_WriteBlock_PS_SWC_DIDMgrDID_FDF0_SleepProcess: start-on-event=WriteBlock, operation=PS_SWC_DIDMgrDID_FDF0_SleepProcess.WriteBlock
        OpEventInvalidateNvBlock_InvalidateNvBlock_PS_SWC_DIDMgrDID_2939_WakeupReason: start-on-event=InvalidateNvBlock, operation=PS_SWC_DIDMgrDID_2939_WakeupReason.InvalidateNvBlock
        OpEventInvalidateNvBlock_InvalidateNvBlock_PS_SWC_DIDMgrDID_FDF0_SleepProcess: start-on-event=InvalidateNvBlock, operation=PS_SWC_DIDMgrDID_FDF0_SleepProcess.InvalidateNvBlock
        OpEventEraseBlock_EraseBlock_PS_SWC_DIDMgrDID_2939_WakeupReason: start-on-event=EraseBlock, operation=PS_SWC_DIDMgrDID_2939_WakeupReason.EraseBlock
        OpEventEraseBlock_EraseBlock_PS_SWC_DIDMgrDID_FDF0_SleepProcess: start-on-event=EraseBlock, operation=PS_SWC_DIDMgrDID_FDF0_SleepProcess.EraseBlock
        OpEventSetBlockProtection_SetBlockProtection_PAdmin_SWC_DIDMgrDID_2939_WakeupReason: start-on-event=SetBlockProtection, operation=PAdmin_SWC_DIDMgrDID_2939_WakeupReason.SetBlockProtection
        OpEventSetBlockProtection_SetBlockProtection_PAdmin_SWC_DIDMgrDID_FDF0_SleepProcess: start-on-event=SetBlockProtection, operation=PAdmin_SWC_DIDMgrDID_FDF0_SleepProcess.SetBlockProtection
        OpEventRestoreBlockDefaults_RestoreBlockDefaults_PS_SWC_DIDMgrDID_2939_WakeupReason: start-on-event=RestoreBlockDefaults, operation=PS_SWC_DIDMgrDID_2939_WakeupReason.RestoreBlockDefaults
        OpEventRestoreBlockDefaults_RestoreBlockDefaults_PS_SWC_DIDMgrDID_FDF0_SleepProcess: start-on-event=RestoreBlockDefaults, operation=PS_SWC_DIDMgrDID_FDF0_SleepProcess.RestoreBlockDefaults
        OpEventGetErrorStatus_GetErrorStatus_PS_SWC_RIDMgrDID_5201_PlantModeStatus: start-on-event=GetErrorStatus, operation=PS_SWC_RIDMgrDID_5201_PlantModeStatus.GetErrorStatus
        OpEventGetErrorStatus_GetErrorStatus_PS_SWC_RIDMgrVIN_CurrentVal: start-on-event=GetErrorStatus, operation=PS_SWC_RIDMgrVIN_CurrentVal.GetErrorStatus
        OpEventGetErrorStatus_GetErrorStatus_PS_SWC_RIDMgrVIN_Lock: start-on-event=GetErrorStatus, operation=PS_SWC_RIDMgrVIN_Lock.GetErrorStatus
        OpEventGetErrorStatus_GetErrorStatus_PS_SWC_RIDMgrVIN_OdometerCnt: start-on-event=GetErrorStatus, operation=PS_SWC_RIDMgrVIN_OdometerCnt.GetErrorStatus
        OpEventGetErrorStatus_GetErrorStatus_PS_SWC_RIDMgrVIN_OriginalVal: start-on-event=GetErrorStatus, operation=PS_SWC_RIDMgrVIN_OriginalVal.GetErrorStatus
        OpEventSetRamBlockStatus_SetRamBlockStatus_PS_SWC_RIDMgrDID_5201_PlantModeStatus: start-on-event=SetRamBlockStatus, operation=PS_SWC_RIDMgrDID_5201_PlantModeStatus.SetRamBlockStatus
        OpEventSetRamBlockStatus_SetRamBlockStatus_PS_SWC_RIDMgrVIN_CurrentVal: start-on-event=SetRamBlockStatus, operation=PS_SWC_RIDMgrVIN_CurrentVal.SetRamBlockStatus
        OpEventSetRamBlockStatus_SetRamBlockStatus_PS_SWC_RIDMgrVIN_Lock: start-on-event=SetRamBlockStatus, operation=PS_SWC_RIDMgrVIN_Lock.SetRamBlockStatus
        OpEventSetRamBlockStatus_SetRamBlockStatus_PS_SWC_RIDMgrVIN_OdometerCnt: start-on-event=SetRamBlockStatus, operation=PS_SWC_RIDMgrVIN_OdometerCnt.SetRamBlockStatus
        OpEventSetRamBlockStatus_SetRamBlockStatus_PS_SWC_RIDMgrVIN_OriginalVal: start-on-event=SetRamBlockStatus, operation=PS_SWC_RIDMgrVIN_OriginalVal.SetRamBlockStatus
        OpEventReadBlock_ReadBlock_PS_SWC_RIDMgrDID_5201_PlantModeStatus: start-on-event=ReadBlock, operation=PS_SWC_RIDMgrDID_5201_PlantModeStatus.ReadBlock
        OpEventReadBlock_ReadBlock_PS_SWC_RIDMgrVIN_CurrentVal: start-on-event=ReadBlock, operation=PS_SWC_RIDMgrVIN_CurrentVal.ReadBlock
        OpEventReadBlock_ReadBlock_PS_SWC_RIDMgrVIN_Lock: start-on-event=ReadBlock, operation=PS_SWC_RIDMgrVIN_Lock.ReadBlock
        OpEventReadBlock_ReadBlock_PS_SWC_RIDMgrVIN_OdometerCnt: start-on-event=ReadBlock, operation=PS_SWC_RIDMgrVIN_OdometerCnt.ReadBlock
        OpEventReadBlock_ReadBlock_PS_SWC_RIDMgrVIN_OriginalVal: start-on-event=ReadBlock, operation=PS_SWC_RIDMgrVIN_OriginalVal.ReadBlock
        OpEventWriteBlock_WriteBlock_PS_SWC_RIDMgrDID_5201_PlantModeStatus: start-on-event=WriteBlock, operation=PS_SWC_RIDMgrDID_5201_PlantModeStatus.WriteBlock
        OpEventWriteBlock_WriteBlock_PS_SWC_RIDMgrVIN_CurrentVal: start-on-event=WriteBlock, operation=PS_SWC_RIDMgrVIN_CurrentVal.WriteBlock
        OpEventWriteBlock_WriteBlock_PS_SWC_RIDMgrVIN_Lock: start-on-event=WriteBlock, operation=PS_SWC_RIDMgrVIN_Lock.WriteBlock
        OpEventWriteBlock_WriteBlock_PS_SWC_RIDMgrVIN_OdometerCnt: start-on-event=WriteBlock, operation=PS_SWC_RIDMgrVIN_OdometerCnt.WriteBlock
        OpEventWriteBlock_WriteBlock_PS_SWC_RIDMgrVIN_OriginalVal: start-on-event=WriteBlock, operation=PS_SWC_RIDMgrVIN_OriginalVal.WriteBlock
        OpEventInvalidateNvBlock_InvalidateNvBlock_PS_SWC_RIDMgrDID_5201_PlantModeStatus: start-on-event=InvalidateNvBlock, operation=PS_SWC_RIDMgrDID_5201_PlantModeStatus.InvalidateNvBlock
        OpEventInvalidateNvBlock_InvalidateNvBlock_PS_SWC_RIDMgrVIN_CurrentVal: start-on-event=InvalidateNvBlock, operation=PS_SWC_RIDMgrVIN_CurrentVal.InvalidateNvBlock
        OpEventInvalidateNvBlock_InvalidateNvBlock_PS_SWC_RIDMgrVIN_Lock: start-on-event=InvalidateNvBlock, operation=PS_SWC_RIDMgrVIN_Lock.InvalidateNvBlock
        OpEventInvalidateNvBlock_InvalidateNvBlock_PS_SWC_RIDMgrVIN_OdometerCnt: start-on-event=InvalidateNvBlock, operation=PS_SWC_RIDMgrVIN_OdometerCnt.InvalidateNvBlock
        OpEventInvalidateNvBlock_InvalidateNvBlock_PS_SWC_RIDMgrVIN_OriginalVal: start-on-event=InvalidateNvBlock, operation=PS_SWC_RIDMgrVIN_OriginalVal.InvalidateNvBlock
        OpEventEraseBlock_EraseBlock_PS_SWC_RIDMgrDID_5201_PlantModeStatus: start-on-event=EraseBlock, operation=PS_SWC_RIDMgrDID_5201_PlantModeStatus.EraseBlock
        OpEventEraseBlock_EraseBlock_PS_SWC_RIDMgrVIN_CurrentVal: start-on-event=EraseBlock, operation=PS_SWC_RIDMgrVIN_CurrentVal.EraseBlock
        OpEventEraseBlock_EraseBlock_PS_SWC_RIDMgrVIN_Lock: start-on-event=EraseBlock, operation=PS_SWC_RIDMgrVIN_Lock.EraseBlock
        OpEventEraseBlock_EraseBlock_PS_SWC_RIDMgrVIN_OdometerCnt: start-on-event=EraseBlock, operation=PS_SWC_RIDMgrVIN_OdometerCnt.EraseBlock
        OpEventEraseBlock_EraseBlock_PS_SWC_RIDMgrVIN_OriginalVal: start-on-event=EraseBlock, operation=PS_SWC_RIDMgrVIN_OriginalVal.EraseBlock
        OpEventSetBlockProtection_SetBlockProtection_PAdmin_SWC_RIDMgrDID_5201_PlantModeStatus: start-on-event=SetBlockProtection, operation=PAdmin_SWC_RIDMgrDID_5201_PlantModeStatus.SetBlockProtection
        OpEventSetBlockProtection_SetBlockProtection_PAdmin_SWC_RIDMgrVIN_CurrentVal: start-on-event=SetBlockProtection, operation=PAdmin_SWC_RIDMgrVIN_CurrentVal.SetBlockProtection
        OpEventSetBlockProtection_SetBlockProtection_PAdmin_SWC_RIDMgrVIN_Lock: start-on-event=SetBlockProtection, operation=PAdmin_SWC_RIDMgrVIN_Lock.SetBlockProtection
        OpEventSetBlockProtection_SetBlockProtection_PAdmin_SWC_RIDMgrVIN_OdometerCnt: start-on-event=SetBlockProtection, operation=PAdmin_SWC_RIDMgrVIN_OdometerCnt.SetBlockProtection
        OpEventSetBlockProtection_SetBlockProtection_PAdmin_SWC_RIDMgrVIN_OriginalVal: start-on-event=SetBlockProtection, operation=PAdmin_SWC_RIDMgrVIN_OriginalVal.SetBlockProtection
        OpEventRestoreBlockDefaults_RestoreBlockDefaults_PS_SWC_RIDMgrDID_5201_PlantModeStatus: start-on-event=RestoreBlockDefaults, operation=PS_SWC_RIDMgrDID_5201_PlantModeStatus.RestoreBlockDefaults
        OpEventRestoreBlockDefaults_RestoreBlockDefaults_PS_SWC_RIDMgrVIN_CurrentVal: start-on-event=RestoreBlockDefaults, operation=PS_SWC_RIDMgrVIN_CurrentVal.RestoreBlockDefaults
        OpEventRestoreBlockDefaults_RestoreBlockDefaults_PS_SWC_RIDMgrVIN_Lock: start-on-event=RestoreBlockDefaults, operation=PS_SWC_RIDMgrVIN_Lock.RestoreBlockDefaults
        OpEventRestoreBlockDefaults_RestoreBlockDefaults_PS_SWC_RIDMgrVIN_OdometerCnt: start-on-event=RestoreBlockDefaults, operation=PS_SWC_RIDMgrVIN_OdometerCnt.RestoreBlockDefaults
        OpEventRestoreBlockDefaults_RestoreBlockDefaults_PS_SWC_RIDMgrVIN_OriginalVal: start-on-event=RestoreBlockDefaults, operation=PS_SWC_RIDMgrVIN_OriginalVal.RestoreBlockDefaults
        OpEventGetErrorStatus_GetErrorStatus_PS_NvMBlockDescriptor_FileHeader: start-on-event=GetErrorStatus, operation=PS_NvMBlockDescriptor_FileHeader.GetErrorStatus
        OpEventSetRamBlockStatus_SetRamBlockStatus_PS_NvMBlockDescriptor_FileHeader: start-on-event=SetRamBlockStatus, operation=PS_NvMBlockDescriptor_FileHeader.SetRamBlockStatus
        OpEventReadBlock_ReadBlock_PS_NvMBlockDescriptor_FileHeader: start-on-event=ReadBlock, operation=PS_NvMBlockDescriptor_FileHeader.ReadBlock
        OpEventWriteBlock_WriteBlock_PS_NvMBlockDescriptor_FileHeader: start-on-event=WriteBlock, operation=PS_NvMBlockDescriptor_FileHeader.WriteBlock
        OpEventSetDataIndex_SetDataIndex_PS_NvMBlockDescriptor_FileHeader: start-on-event=SetDataIndex, operation=PS_NvMBlockDescriptor_FileHeader.SetDataIndex
        OpEventGetDataIndex_GetDataIndex_PS_NvMBlockDescriptor_FileHeader: start-on-event=GetDataIndex, operation=PS_NvMBlockDescriptor_FileHeader.GetDataIndex
        OpEventInvalidateNvBlock_InvalidateNvBlock_PS_NvMBlockDescriptor_FileHeader: start-on-event=InvalidateNvBlock, operation=PS_NvMBlockDescriptor_FileHeader.InvalidateNvBlock
        OpEventEraseBlock_EraseBlock_PS_NvMBlockDescriptor_FileHeader: start-on-event=EraseBlock, operation=PS_NvMBlockDescriptor_FileHeader.EraseBlock
        OpEventSetBlockProtection_SetBlockProtection_PAdmin_NvMBlockDescriptor_FileHeader: start-on-event=SetBlockProtection, operation=PAdmin_NvMBlockDescriptor_FileHeader.SetBlockProtection
        OpEventGetErrorStatus_GetErrorStatus_PS_CDD_IPCHandlerFPA_SlotData: start-on-event=GetErrorStatus, operation=PS_CDD_IPCHandlerFPA_SlotData.GetErrorStatus
        OpEventSetRamBlockStatus_SetRamBlockStatus_PS_CDD_IPCHandlerFPA_SlotData: start-on-event=SetRamBlockStatus, operation=PS_CDD_IPCHandlerFPA_SlotData.SetRamBlockStatus
        OpEventReadBlock_ReadBlock_PS_CDD_IPCHandlerFPA_SlotData: start-on-event=ReadBlock, operation=PS_CDD_IPCHandlerFPA_SlotData.ReadBlock
        OpEventWriteBlock_WriteBlock_PS_CDD_IPCHandlerFPA_SlotData: start-on-event=WriteBlock, operation=PS_CDD_IPCHandlerFPA_SlotData.WriteBlock
        OpEventInvalidateNvBlock_InvalidateNvBlock_PS_CDD_IPCHandlerFPA_SlotData: start-on-event=InvalidateNvBlock, operation=PS_CDD_IPCHandlerFPA_SlotData.InvalidateNvBlock
        OpEventEraseBlock_EraseBlock_PS_CDD_IPCHandlerFPA_SlotData: start-on-event=EraseBlock, operation=PS_CDD_IPCHandlerFPA_SlotData.EraseBlock
        OpEventSetBlockProtection_SetBlockProtection_PAdmin_CDD_IPCHandlerFPA_SlotData: start-on-event=SetBlockProtection, operation=PAdmin_CDD_IPCHandlerFPA_SlotData.SetBlockProtection
        OpEventRestoreBlockDefaults_RestoreBlockDefaults_PS_CDD_IPCHandlerFPA_SlotData: start-on-event=RestoreBlockDefaults, operation=PS_CDD_IPCHandlerFPA_SlotData.RestoreBlockDefaults
        OpEventGetErrorStatus_GetErrorStatus_PS_CDD_CryptoMgrNvMBlockDescriptor_SecAccessDelayFlag: start-on-event=GetErrorStatus, operation=PS_CDD_CryptoMgrNvMBlockDescriptor_SecAccessDelayFlag.GetErrorStatus
        OpEventGetErrorStatus_GetErrorStatus_PS_CDD_CryptoMgrNvMBlockDescriptor_SecAccessInvalidCount: start-on-event=GetErrorStatus, operation=PS_CDD_CryptoMgrNvMBlockDescriptor_SecAccessInvalidCount.GetErrorStatus
        OpEventSetRamBlockStatus_SetRamBlockStatus_PS_CDD_CryptoMgrNvMBlockDescriptor_SecAccessDelayFlag: start-on-event=SetRamBlockStatus, operation=PS_CDD_CryptoMgrNvMBlockDescriptor_SecAccessDelayFlag.SetRamBlockStatus
        OpEventSetRamBlockStatus_SetRamBlockStatus_PS_CDD_CryptoMgrNvMBlockDescriptor_SecAccessInvalidCount: start-on-event=SetRamBlockStatus, operation=PS_CDD_CryptoMgrNvMBlockDescriptor_SecAccessInvalidCount.SetRamBlockStatus
        OpEventReadBlock_ReadBlock_PS_CDD_CryptoMgrNvMBlockDescriptor_SecAccessDelayFlag: start-on-event=ReadBlock, operation=PS_CDD_CryptoMgrNvMBlockDescriptor_SecAccessDelayFlag.ReadBlock
        OpEventReadBlock_ReadBlock_PS_CDD_CryptoMgrNvMBlockDescriptor_SecAccessInvalidCount: start-on-event=ReadBlock, operation=PS_CDD_CryptoMgrNvMBlockDescriptor_SecAccessInvalidCount.ReadBlock
        OpEventWriteBlock_WriteBlock_PS_CDD_CryptoMgrNvMBlockDescriptor_SecAccessDelayFlag: start-on-event=WriteBlock, operation=PS_CDD_CryptoMgrNvMBlockDescriptor_SecAccessDelayFlag.WriteBlock
        OpEventWriteBlock_WriteBlock_PS_CDD_CryptoMgrNvMBlockDescriptor_SecAccessInvalidCount: start-on-event=WriteBlock, operation=PS_CDD_CryptoMgrNvMBlockDescriptor_SecAccessInvalidCount.WriteBlock
        OpEventRestoreBlockDefaults_RestoreBlockDefaults_PS_CDD_CryptoMgrNvMBlockDescriptor_SecAccessDelayFlag: start-on-event=RestoreBlockDefaults, operation=PS_CDD_CryptoMgrNvMBlockDescriptor_SecAccessDelayFlag.RestoreBlockDefaults
        OpEventRestoreBlockDefaults_RestoreBlockDefaults_PS_CDD_CryptoMgrNvMBlockDescriptor_SecAccessInvalidCount: start-on-event=RestoreBlockDefaults, operation=PS_CDD_CryptoMgrNvMBlockDescriptor_SecAccessInvalidCount.RestoreBlockDefaults
        OpEventInvalidateNvBlock_InvalidateNvBlock_PS_CDD_CryptoMgrNvMBlockDescriptor_SecAccessDelayFlag: start-on-event=InvalidateNvBlock, operation=PS_CDD_CryptoMgrNvMBlockDescriptor_SecAccessDelayFlag.InvalidateNvBlock
        OpEventInvalidateNvBlock_InvalidateNvBlock_PS_CDD_CryptoMgrNvMBlockDescriptor_SecAccessInvalidCount: start-on-event=InvalidateNvBlock, operation=PS_CDD_CryptoMgrNvMBlockDescriptor_SecAccessInvalidCount.InvalidateNvBlock
        OpEventEraseBlock_EraseBlock_PS_CDD_CryptoMgrNvMBlockDescriptor_SecAccessDelayFlag: start-on-event=EraseBlock, operation=PS_CDD_CryptoMgrNvMBlockDescriptor_SecAccessDelayFlag.EraseBlock
        OpEventEraseBlock_EraseBlock_PS_CDD_CryptoMgrNvMBlockDescriptor_SecAccessInvalidCount: start-on-event=EraseBlock, operation=PS_CDD_CryptoMgrNvMBlockDescriptor_SecAccessInvalidCount.EraseBlock
        OpEventSetBlockProtection_SetBlockProtection_PAdmin_CDD_CryptoMgrNvMBlockDescriptor_SecAccessDelayFlag: start-on-event=SetBlockProtection, operation=PAdmin_CDD_CryptoMgrNvMBlockDescriptor_SecAccessDelayFlag.SetBlockProtection
        OpEventSetBlockProtection_SetBlockProtection_PAdmin_CDD_CryptoMgrNvMBlockDescriptor_SecAccessInvalidCount: start-on-event=SetBlockProtection, operation=PAdmin_CDD_CryptoMgrNvMBlockDescriptor_SecAccessInvalidCount.SetBlockProtection
        OpEventGetErrorStatus_GetErrorStatus_PS_NvMBlockDescriptor_CertAccessInfo: start-on-event=GetErrorStatus, operation=PS_NvMBlockDescriptor_CertAccessInfo.GetErrorStatus
        OpEventSetRamBlockStatus_SetRamBlockStatus_PS_NvMBlockDescriptor_CertAccessInfo: start-on-event=SetRamBlockStatus, operation=PS_NvMBlockDescriptor_CertAccessInfo.SetRamBlockStatus
        OpEventReadBlock_ReadBlock_PS_NvMBlockDescriptor_CertAccessInfo: start-on-event=ReadBlock, operation=PS_NvMBlockDescriptor_CertAccessInfo.ReadBlock
        OpEventWriteBlock_WriteBlock_PS_NvMBlockDescriptor_CertAccessInfo: start-on-event=WriteBlock, operation=PS_NvMBlockDescriptor_CertAccessInfo.WriteBlock
        OpEventInvalidateNvBlock_InvalidateNvBlock_PS_NvMBlockDescriptor_CertAccessInfo: start-on-event=InvalidateNvBlock, operation=PS_NvMBlockDescriptor_CertAccessInfo.InvalidateNvBlock
        OpEventEraseBlock_EraseBlock_PS_NvMBlockDescriptor_CertAccessInfo: start-on-event=EraseBlock, operation=PS_NvMBlockDescriptor_CertAccessInfo.EraseBlock
        OpEventSetBlockProtection_SetBlockProtection_PAdmin_NvMBlockDescriptor_CertAccessInfo: start-on-event=SetBlockProtection, operation=PAdmin_NvMBlockDescriptor_CertAccessInfo.SetBlockProtection
        OpEventSetDataIndex_SetDataIndex_PS_NvMBlockDescriptor_CertAccessInfo: start-on-event=SetDataIndex, operation=PS_NvMBlockDescriptor_CertAccessInfo.SetDataIndex
        OpEventGetDataIndex_GetDataIndex_PS_NvMBlockDescriptor_CertAccessInfo: start-on-event=GetDataIndex, operation=PS_NvMBlockDescriptor_CertAccessInfo.GetDataIndex
        OpEventGetErrorStatus_GetErrorStatus_PS_CDD_CryptoMgrNvMBlockDescriptor_SecureLogGroup1: start-on-event=GetErrorStatus, operation=PS_CDD_CryptoMgrNvMBlockDescriptor_SecureLogGroup1.GetErrorStatus
        OpEventGetErrorStatus_GetErrorStatus_PS_CDD_CryptoMgrNvMBlockDescriptor_SecureLogGroup2: start-on-event=GetErrorStatus, operation=PS_CDD_CryptoMgrNvMBlockDescriptor_SecureLogGroup2.GetErrorStatus
        OpEventSetRamBlockStatus_SetRamBlockStatus_PS_CDD_CryptoMgrNvMBlockDescriptor_SecureLogGroup1: start-on-event=SetRamBlockStatus, operation=PS_CDD_CryptoMgrNvMBlockDescriptor_SecureLogGroup1.SetRamBlockStatus
        OpEventSetRamBlockStatus_SetRamBlockStatus_PS_CDD_CryptoMgrNvMBlockDescriptor_SecureLogGroup2: start-on-event=SetRamBlockStatus, operation=PS_CDD_CryptoMgrNvMBlockDescriptor_SecureLogGroup2.SetRamBlockStatus
        OpEventReadBlock_ReadBlock_PS_CDD_CryptoMgrNvMBlockDescriptor_SecureLogGroup1: start-on-event=ReadBlock, operation=PS_CDD_CryptoMgrNvMBlockDescriptor_SecureLogGroup1.ReadBlock
        OpEventReadBlock_ReadBlock_PS_CDD_CryptoMgrNvMBlockDescriptor_SecureLogGroup2: start-on-event=ReadBlock, operation=PS_CDD_CryptoMgrNvMBlockDescriptor_SecureLogGroup2.ReadBlock
        OpEventWriteBlock_WriteBlock_PS_CDD_CryptoMgrNvMBlockDescriptor_SecureLogGroup1: start-on-event=WriteBlock, operation=PS_CDD_CryptoMgrNvMBlockDescriptor_SecureLogGroup1.WriteBlock
        OpEventWriteBlock_WriteBlock_PS_CDD_CryptoMgrNvMBlockDescriptor_SecureLogGroup2: start-on-event=WriteBlock, operation=PS_CDD_CryptoMgrNvMBlockDescriptor_SecureLogGroup2.WriteBlock
        OpEventRestoreBlockDefaults_RestoreBlockDefaults_PS_CDD_CryptoMgrNvMBlockDescriptor_SecureLogGroup1: start-on-event=RestoreBlockDefaults, operation=PS_CDD_CryptoMgrNvMBlockDescriptor_SecureLogGroup1.RestoreBlockDefaults
        OpEventRestoreBlockDefaults_RestoreBlockDefaults_PS_CDD_CryptoMgrNvMBlockDescriptor_SecureLogGroup2: start-on-event=RestoreBlockDefaults, operation=PS_CDD_CryptoMgrNvMBlockDescriptor_SecureLogGroup2.RestoreBlockDefaults
        OpEventInvalidateNvBlock_InvalidateNvBlock_PS_CDD_CryptoMgrNvMBlockDescriptor_SecureLogGroup1: start-on-event=InvalidateNvBlock, operation=PS_CDD_CryptoMgrNvMBlockDescriptor_SecureLogGroup1.InvalidateNvBlock
        OpEventInvalidateNvBlock_InvalidateNvBlock_PS_CDD_CryptoMgrNvMBlockDescriptor_SecureLogGroup2: start-on-event=InvalidateNvBlock, operation=PS_CDD_CryptoMgrNvMBlockDescriptor_SecureLogGroup2.InvalidateNvBlock
        OpEventEraseBlock_EraseBlock_PS_CDD_CryptoMgrNvMBlockDescriptor_SecureLogGroup1: start-on-event=EraseBlock, operation=PS_CDD_CryptoMgrNvMBlockDescriptor_SecureLogGroup1.EraseBlock
        OpEventEraseBlock_EraseBlock_PS_CDD_CryptoMgrNvMBlockDescriptor_SecureLogGroup2: start-on-event=EraseBlock, operation=PS_CDD_CryptoMgrNvMBlockDescriptor_SecureLogGroup2.EraseBlock
        OpEventSetBlockProtection_SetBlockProtection_PAdmin_CDD_CryptoMgrNvMBlockDescriptor_SecureLogGroup1: start-on-event=SetBlockProtection, operation=PAdmin_CDD_CryptoMgrNvMBlockDescriptor_SecureLogGroup1.SetBlockProtection
        OpEventSetBlockProtection_SetBlockProtection_PAdmin_CDD_CryptoMgrNvMBlockDescriptor_SecureLogGroup2: start-on-event=SetBlockProtection, operation=PAdmin_CDD_CryptoMgrNvMBlockDescriptor_SecureLogGroup2.SetBlockProtection
        OpEventGetErrorStatus_GetErrorStatus_PS_Safety_GuardSafeStat2_ResetReason: start-on-event=GetErrorStatus, operation=PS_Safety_GuardSafeStat2_ResetReason.GetErrorStatus
        OpEventSetRamBlockStatus_SetRamBlockStatus_PS_Safety_GuardSafeStat2_ResetReason: start-on-event=SetRamBlockStatus, operation=PS_Safety_GuardSafeStat2_ResetReason.SetRamBlockStatus
        OpEventReadBlock_ReadBlock_PS_Safety_GuardSafeStat2_ResetReason: start-on-event=ReadBlock, operation=PS_Safety_GuardSafeStat2_ResetReason.ReadBlock
        OpEventWriteBlock_WriteBlock_PS_Safety_GuardSafeStat2_ResetReason: start-on-event=WriteBlock, operation=PS_Safety_GuardSafeStat2_ResetReason.WriteBlock
        OpEventRestoreBlockDefaults_RestoreBlockDefaults_PS_Safety_GuardSafeStat2_ResetReason: start-on-event=RestoreBlockDefaults, operation=PS_Safety_GuardSafeStat2_ResetReason.RestoreBlockDefaults
        OpEventInvalidateNvBlock_InvalidateNvBlock_PS_Safety_GuardSafeStat2_ResetReason: start-on-event=InvalidateNvBlock, operation=PS_Safety_GuardSafeStat2_ResetReason.InvalidateNvBlock
        OpEventEraseBlock_EraseBlock_PS_Safety_GuardSafeStat2_ResetReason: start-on-event=EraseBlock, operation=PS_Safety_GuardSafeStat2_ResetReason.EraseBlock
        OpEventSetBlockProtection_SetBlockProtection_PAdmin_Safety_GuardSafeStat2_ResetReason: start-on-event=SetBlockProtection, operation=PAdmin_Safety_GuardSafeStat2_ResetReason.SetBlockProtection
        OpEventGetErrorStatus_GetErrorStatus_PS_CalDataProviderFrontCamSerialNumber: start-on-event=GetErrorStatus, operation=PS_CalDataProviderFrontCamSerialNumber.GetErrorStatus
        OpEventGetErrorStatus_GetErrorStatus_PS_CalDataProviderLeftCamSerialNumber: start-on-event=GetErrorStatus, operation=PS_CalDataProviderLeftCamSerialNumber.GetErrorStatus
        OpEventGetErrorStatus_GetErrorStatus_PS_CalDataProviderRearCamSerialNumber: start-on-event=GetErrorStatus, operation=PS_CalDataProviderRearCamSerialNumber.GetErrorStatus
        OpEventGetErrorStatus_GetErrorStatus_PS_CalDataProviderRightCamSerialNumber: start-on-event=GetErrorStatus, operation=PS_CalDataProviderRightCamSerialNumber.GetErrorStatus
        OpEventSetRamBlockStatus_SetRamBlockStatus_PS_CalDataProviderFrontCamSerialNumber: start-on-event=SetRamBlockStatus, operation=PS_CalDataProviderFrontCamSerialNumber.SetRamBlockStatus
        OpEventSetRamBlockStatus_SetRamBlockStatus_PS_CalDataProviderLeftCamSerialNumber: start-on-event=SetRamBlockStatus, operation=PS_CalDataProviderLeftCamSerialNumber.SetRamBlockStatus
        OpEventSetRamBlockStatus_SetRamBlockStatus_PS_CalDataProviderRearCamSerialNumber: start-on-event=SetRamBlockStatus, operation=PS_CalDataProviderRearCamSerialNumber.SetRamBlockStatus
        OpEventSetRamBlockStatus_SetRamBlockStatus_PS_CalDataProviderRightCamSerialNumber: start-on-event=SetRamBlockStatus, operation=PS_CalDataProviderRightCamSerialNumber.SetRamBlockStatus
        OpEventReadBlock_ReadBlock_PS_CalDataProviderFrontCamSerialNumber: start-on-event=ReadBlock, operation=PS_CalDataProviderFrontCamSerialNumber.ReadBlock
        OpEventReadBlock_ReadBlock_PS_CalDataProviderLeftCamSerialNumber: start-on-event=ReadBlock, operation=PS_CalDataProviderLeftCamSerialNumber.ReadBlock
        OpEventReadBlock_ReadBlock_PS_CalDataProviderRearCamSerialNumber: start-on-event=ReadBlock, operation=PS_CalDataProviderRearCamSerialNumber.ReadBlock
        OpEventReadBlock_ReadBlock_PS_CalDataProviderRightCamSerialNumber: start-on-event=ReadBlock, operation=PS_CalDataProviderRightCamSerialNumber.ReadBlock
        OpEventWriteBlock_WriteBlock_PS_CalDataProviderFrontCamSerialNumber: start-on-event=WriteBlock, operation=PS_CalDataProviderFrontCamSerialNumber.WriteBlock
        OpEventWriteBlock_WriteBlock_PS_CalDataProviderLeftCamSerialNumber: start-on-event=WriteBlock, operation=PS_CalDataProviderLeftCamSerialNumber.WriteBlock
        OpEventWriteBlock_WriteBlock_PS_CalDataProviderRearCamSerialNumber: start-on-event=WriteBlock, operation=PS_CalDataProviderRearCamSerialNumber.WriteBlock
        OpEventWriteBlock_WriteBlock_PS_CalDataProviderRightCamSerialNumber: start-on-event=WriteBlock, operation=PS_CalDataProviderRightCamSerialNumber.WriteBlock
        OpEventRestoreBlockDefaults_RestoreBlockDefaults_PS_CalDataProviderFrontCamSerialNumber: start-on-event=RestoreBlockDefaults, operation=PS_CalDataProviderFrontCamSerialNumber.RestoreBlockDefaults
        OpEventRestoreBlockDefaults_RestoreBlockDefaults_PS_CalDataProviderLeftCamSerialNumber: start-on-event=RestoreBlockDefaults, operation=PS_CalDataProviderLeftCamSerialNumber.RestoreBlockDefaults
        OpEventRestoreBlockDefaults_RestoreBlockDefaults_PS_CalDataProviderRearCamSerialNumber: start-on-event=RestoreBlockDefaults, operation=PS_CalDataProviderRearCamSerialNumber.RestoreBlockDefaults
        OpEventRestoreBlockDefaults_RestoreBlockDefaults_PS_CalDataProviderRightCamSerialNumber: start-on-event=RestoreBlockDefaults, operation=PS_CalDataProviderRightCamSerialNumber.RestoreBlockDefaults
        OpEventInvalidateNvBlock_InvalidateNvBlock_PS_CalDataProviderFrontCamSerialNumber: start-on-event=InvalidateNvBlock, operation=PS_CalDataProviderFrontCamSerialNumber.InvalidateNvBlock
        OpEventInvalidateNvBlock_InvalidateNvBlock_PS_CalDataProviderLeftCamSerialNumber: start-on-event=InvalidateNvBlock, operation=PS_CalDataProviderLeftCamSerialNumber.InvalidateNvBlock
        OpEventInvalidateNvBlock_InvalidateNvBlock_PS_CalDataProviderRearCamSerialNumber: start-on-event=InvalidateNvBlock, operation=PS_CalDataProviderRearCamSerialNumber.InvalidateNvBlock
        OpEventInvalidateNvBlock_InvalidateNvBlock_PS_CalDataProviderRightCamSerialNumber: start-on-event=InvalidateNvBlock, operation=PS_CalDataProviderRightCamSerialNumber.InvalidateNvBlock
        OpEventEraseBlock_EraseBlock_PS_CalDataProviderFrontCamSerialNumber: start-on-event=EraseBlock, operation=PS_CalDataProviderFrontCamSerialNumber.EraseBlock
        OpEventEraseBlock_EraseBlock_PS_CalDataProviderLeftCamSerialNumber: start-on-event=EraseBlock, operation=PS_CalDataProviderLeftCamSerialNumber.EraseBlock
        OpEventEraseBlock_EraseBlock_PS_CalDataProviderRearCamSerialNumber: start-on-event=EraseBlock, operation=PS_CalDataProviderRearCamSerialNumber.EraseBlock
        OpEventEraseBlock_EraseBlock_PS_CalDataProviderRightCamSerialNumber: start-on-event=EraseBlock, operation=PS_CalDataProviderRightCamSerialNumber.EraseBlock
        OpEventSetBlockProtection_SetBlockProtection_PAdmin_CalDataProviderFrontCamSerialNumber: start-on-event=SetBlockProtection, operation=PAdmin_CalDataProviderFrontCamSerialNumber.SetBlockProtection
        OpEventSetBlockProtection_SetBlockProtection_PAdmin_CalDataProviderLeftCamSerialNumber: start-on-event=SetBlockProtection, operation=PAdmin_CalDataProviderLeftCamSerialNumber.SetBlockProtection
        OpEventSetBlockProtection_SetBlockProtection_PAdmin_CalDataProviderRearCamSerialNumber: start-on-event=SetBlockProtection, operation=PAdmin_CalDataProviderRearCamSerialNumber.SetBlockProtection
        OpEventSetBlockProtection_SetBlockProtection_PAdmin_CalDataProviderRightCamSerialNumber: start-on-event=SetBlockProtection, operation=PAdmin_CalDataProviderRightCamSerialNumber.SetBlockProtection
        OpEventGetErrorStatus_GetErrorStatus_PS_CDD_SafetyCDD_PMICLastResetReason_BISTStatus: start-on-event=GetErrorStatus, operation=PS_CDD_SafetyCDD_PMICLastResetReason_BISTStatus.GetErrorStatus
        OpEventSetRamBlockStatus_SetRamBlockStatus_PS_CDD_SafetyCDD_PMICLastResetReason_BISTStatus: start-on-event=SetRamBlockStatus, operation=PS_CDD_SafetyCDD_PMICLastResetReason_BISTStatus.SetRamBlockStatus
        OpEventReadBlock_ReadBlock_PS_CDD_SafetyCDD_PMICLastResetReason_BISTStatus: start-on-event=ReadBlock, operation=PS_CDD_SafetyCDD_PMICLastResetReason_BISTStatus.ReadBlock
        OpEventWriteBlock_WriteBlock_PS_CDD_SafetyCDD_PMICLastResetReason_BISTStatus: start-on-event=WriteBlock, operation=PS_CDD_SafetyCDD_PMICLastResetReason_BISTStatus.WriteBlock
        OpEventRestoreBlockDefaults_RestoreBlockDefaults_PS_CDD_SafetyCDD_PMICLastResetReason_BISTStatus: start-on-event=RestoreBlockDefaults, operation=PS_CDD_SafetyCDD_PMICLastResetReason_BISTStatus.RestoreBlockDefaults
        OpEventInvalidateNvBlock_InvalidateNvBlock_PS_CDD_SafetyCDD_PMICLastResetReason_BISTStatus: start-on-event=InvalidateNvBlock, operation=PS_CDD_SafetyCDD_PMICLastResetReason_BISTStatus.InvalidateNvBlock
        OpEventEraseBlock_EraseBlock_PS_CDD_SafetyCDD_PMICLastResetReason_BISTStatus: start-on-event=EraseBlock, operation=PS_CDD_SafetyCDD_PMICLastResetReason_BISTStatus.EraseBlock
        OpEventSetBlockProtection_SetBlockProtection_PAdmin_CDD_SafetyCDD_PMICLastResetReason_BISTStatus: start-on-event=SetBlockProtection, operation=PAdmin_CDD_SafetyCDD_PMICLastResetReason_BISTStatus.SetBlockProtection
        OpEventGetErrorStatus_GetErrorStatus_PS_SWC_DIDMgrDID_FD74_BuffMarkCompErr: start-on-event=GetErrorStatus, operation=PS_SWC_DIDMgrDID_FD74_BuffMarkCompErr.GetErrorStatus
        OpEventGetErrorStatus_GetErrorStatus_PS_SWC_DIDMgrDID_FD74_PHY_TuningErr: start-on-event=GetErrorStatus, operation=PS_SWC_DIDMgrDID_FD74_PHY_TuningErr.GetErrorStatus
        OpEventSetRamBlockStatus_SetRamBlockStatus_PS_SWC_DIDMgrDID_FD74_BuffMarkCompErr: start-on-event=SetRamBlockStatus, operation=PS_SWC_DIDMgrDID_FD74_BuffMarkCompErr.SetRamBlockStatus
        OpEventSetRamBlockStatus_SetRamBlockStatus_PS_SWC_DIDMgrDID_FD74_PHY_TuningErr: start-on-event=SetRamBlockStatus, operation=PS_SWC_DIDMgrDID_FD74_PHY_TuningErr.SetRamBlockStatus
        OpEventReadBlock_ReadBlock_PS_SWC_DIDMgrDID_FD74_BuffMarkCompErr: start-on-event=ReadBlock, operation=PS_SWC_DIDMgrDID_FD74_BuffMarkCompErr.ReadBlock
        OpEventReadBlock_ReadBlock_PS_SWC_DIDMgrDID_FD74_PHY_TuningErr: start-on-event=ReadBlock, operation=PS_SWC_DIDMgrDID_FD74_PHY_TuningErr.ReadBlock
        OpEventWriteBlock_WriteBlock_PS_SWC_DIDMgrDID_FD74_BuffMarkCompErr: start-on-event=WriteBlock, operation=PS_SWC_DIDMgrDID_FD74_BuffMarkCompErr.WriteBlock
        OpEventWriteBlock_WriteBlock_PS_SWC_DIDMgrDID_FD74_PHY_TuningErr: start-on-event=WriteBlock, operation=PS_SWC_DIDMgrDID_FD74_PHY_TuningErr.WriteBlock
        OpEventRestoreBlockDefaults_RestoreBlockDefaults_PS_SWC_DIDMgrDID_FD74_BuffMarkCompErr: start-on-event=RestoreBlockDefaults, operation=PS_SWC_DIDMgrDID_FD74_BuffMarkCompErr.RestoreBlockDefaults
        OpEventRestoreBlockDefaults_RestoreBlockDefaults_PS_SWC_DIDMgrDID_FD74_PHY_TuningErr: start-on-event=RestoreBlockDefaults, operation=PS_SWC_DIDMgrDID_FD74_PHY_TuningErr.RestoreBlockDefaults
        OpEventInvalidateNvBlock_InvalidateNvBlock_PS_SWC_DIDMgrDID_FD74_BuffMarkCompErr: start-on-event=InvalidateNvBlock, operation=PS_SWC_DIDMgrDID_FD74_BuffMarkCompErr.InvalidateNvBlock
        OpEventInvalidateNvBlock_InvalidateNvBlock_PS_SWC_DIDMgrDID_FD74_PHY_TuningErr: start-on-event=InvalidateNvBlock, operation=PS_SWC_DIDMgrDID_FD74_PHY_TuningErr.InvalidateNvBlock
        OpEventEraseBlock_EraseBlock_PS_SWC_DIDMgrDID_FD74_BuffMarkCompErr: start-on-event=EraseBlock, operation=PS_SWC_DIDMgrDID_FD74_BuffMarkCompErr.EraseBlock
        OpEventEraseBlock_EraseBlock_PS_SWC_DIDMgrDID_FD74_PHY_TuningErr: start-on-event=EraseBlock, operation=PS_SWC_DIDMgrDID_FD74_PHY_TuningErr.EraseBlock
        OpEventSetBlockProtection_SetBlockProtection_PAdmin_SWC_DIDMgrDID_FD74_BuffMarkCompErr: start-on-event=SetBlockProtection, operation=PAdmin_SWC_DIDMgrDID_FD74_BuffMarkCompErr.SetBlockProtection
        OpEventSetBlockProtection_SetBlockProtection_PAdmin_SWC_DIDMgrDID_FD74_PHY_TuningErr: start-on-event=SetBlockProtection, operation=PAdmin_SWC_DIDMgrDID_FD74_PHY_TuningErr.SetBlockProtection
        OpEventGetErrorStatus_GetErrorStatus_PS_SWC_DTCMgrDTC_APARequestSts_PAMRequestSts: start-on-event=GetErrorStatus, operation=PS_SWC_DTCMgrDTC_APARequestSts_PAMRequestSts.GetErrorStatus
        OpEventSetRamBlockStatus_SetRamBlockStatus_PS_SWC_DTCMgrDTC_APARequestSts_PAMRequestSts: start-on-event=SetRamBlockStatus, operation=PS_SWC_DTCMgrDTC_APARequestSts_PAMRequestSts.SetRamBlockStatus
        OpEventReadBlock_ReadBlock_PS_SWC_DTCMgrDTC_APARequestSts_PAMRequestSts: start-on-event=ReadBlock, operation=PS_SWC_DTCMgrDTC_APARequestSts_PAMRequestSts.ReadBlock
        OpEventWriteBlock_WriteBlock_PS_SWC_DTCMgrDTC_APARequestSts_PAMRequestSts: start-on-event=WriteBlock, operation=PS_SWC_DTCMgrDTC_APARequestSts_PAMRequestSts.WriteBlock
        OpEventInvalidateNvBlock_InvalidateNvBlock_PS_SWC_DTCMgrDTC_APARequestSts_PAMRequestSts: start-on-event=InvalidateNvBlock, operation=PS_SWC_DTCMgrDTC_APARequestSts_PAMRequestSts.InvalidateNvBlock
        OpEventEraseBlock_EraseBlock_PS_SWC_DTCMgrDTC_APARequestSts_PAMRequestSts: start-on-event=EraseBlock, operation=PS_SWC_DTCMgrDTC_APARequestSts_PAMRequestSts.EraseBlock
        OpEventSetBlockProtection_SetBlockProtection_PAdmin_SWC_DTCMgrDTC_APARequestSts_PAMRequestSts: start-on-event=SetBlockProtection, operation=PAdmin_SWC_DTCMgrDTC_APARequestSts_PAMRequestSts.SetBlockProtection
        OpEventRestoreBlockDefaults_RestoreBlockDefaults_PS_SWC_DTCMgrDTC_APARequestSts_PAMRequestSts: start-on-event=RestoreBlockDefaults, operation=PS_SWC_DTCMgrDTC_APARequestSts_PAMRequestSts.RestoreBlockDefaults
      port-api-options:
        enable-take-address=true, indirect-api=false, port=NvM_RpNotifyJobEnd_NvMBlockDescriptor_MetaData
        {enable-take-address=true, indirect-api=false, port-defined-argument-value{value=12, value-type=NvM_BlockIdType}, port=PS_NvMBlockDescriptor_MetaData}
        {enable-take-address=true, indirect-api=false, port-defined-argument-value{value=12, value-type=NvM_BlockIdType}, port=PAdmin_NvMBlockDescriptor_MetaData}
        {enable-take-address=true, indirect-api=false, port-defined-argument-value{value=10, value-type=NvM_BlockIdType}, port=PS_SWC_PartNumMgrDID_F180_Boot_SW_Ver_Info}
        {enable-take-address=true, indirect-api=false, port-defined-argument-value{value=10, value-type=NvM_BlockIdType}, port=PAdmin_SWC_PartNumMgrDID_F180_Boot_SW_Ver_Info}
        {enable-take-address=true, indirect-api=false, port-defined-argument-value{value=47, value-type=NvM_BlockIdType}, port=PS_SWC_DIDMgrDID_191D_PowerLatch}
        {enable-take-address=true, indirect-api=false, port-defined-argument-value{value=47, value-type=NvM_BlockIdType}, port=PAdmin_SWC_DIDMgrDID_191D_PowerLatch}
        {enable-take-address=true, indirect-api=false, port-defined-argument-value{value=25, value-type=NvM_BlockIdType}, port=PS_SWC_DIDMgrDID_2002_OdoFlashing}
        {enable-take-address=true, indirect-api=false, port-defined-argument-value{value=25, value-type=NvM_BlockIdType}, port=PAdmin_SWC_DIDMgrDID_2002_OdoFlashing}
        {enable-take-address=true, indirect-api=false, port-defined-argument-value{value=55, value-type=NvM_BlockIdType}, port=PS_SWC_DIDMgrDID_2002_ProgReqFlag}
        {enable-take-address=true, indirect-api=false, port-defined-argument-value{value=55, value-type=NvM_BlockIdType}, port=PAdmin_SWC_DIDMgrDID_2002_ProgReqFlag}
        {enable-take-address=true, indirect-api=false, port-defined-argument-value{value=48, value-type=NvM_BlockIdType}, port=PS_SWC_DIDMgrDID_200A_IgOnCounter}
        {enable-take-address=true, indirect-api=false, port-defined-argument-value{value=48, value-type=NvM_BlockIdType}, port=PAdmin_SWC_DIDMgrDID_200A_IgOnCounter}
        {enable-take-address=true, indirect-api=false, port-defined-argument-value{value=49, value-type=NvM_BlockIdType}, port=PS_SWC_DIDMgrDID_200B_TimeSinceFirstDTC}
        {enable-take-address=true, indirect-api=false, port-defined-argument-value{value=49, value-type=NvM_BlockIdType}, port=PAdmin_SWC_DIDMgrDID_200B_TimeSinceFirstDTC}
        {enable-take-address=true, indirect-api=false, port-defined-argument-value{value=50, value-type=NvM_BlockIdType}, port=PS_SWC_DIDMgrDID_200C_TimeSinceIgnOnFirstDTC}
        {enable-take-address=true, indirect-api=false, port-defined-argument-value{value=50, value-type=NvM_BlockIdType}, port=PAdmin_SWC_DIDMgrDID_200C_TimeSinceIgnOnFirstDTC}
        {enable-take-address=true, indirect-api=false, port-defined-argument-value{value=51, value-type=NvM_BlockIdType}, port=PS_SWC_DIDMgrDID_200D_LastClearDTCOdo}
        {enable-take-address=true, indirect-api=false, port-defined-argument-value{value=51, value-type=NvM_BlockIdType}, port=PAdmin_SWC_DIDMgrDID_200D_LastClearDTCOdo}
        {enable-take-address=true, indirect-api=false, port-defined-argument-value{value=56, value-type=NvM_BlockIdType}, port=PS_SWC_DIDMgrDID_FD33_MagnaTesting}
        {enable-take-address=true, indirect-api=false, port-defined-argument-value{value=56, value-type=NvM_BlockIdType}, port=PAdmin_SWC_DIDMgrDID_FD33_MagnaTesting}
        {enable-take-address=true, indirect-api=false, port-defined-argument-value{value=52, value-type=NvM_BlockIdType}, port=PS_SWC_DIDMgrECU_LifeTime}
        {enable-take-address=true, indirect-api=false, port-defined-argument-value{value=52, value-type=NvM_BlockIdType}, port=PAdmin_SWC_DIDMgrECU_LifeTime}
        {enable-take-address=true, indirect-api=false, port-defined-argument-value{value=46, value-type=NvM_BlockIdType}, port=PS_SWC_DIDMgr_vRoE_Activation_State}
        {enable-take-address=true, indirect-api=false, port-defined-argument-value{value=46, value-type=NvM_BlockIdType}, port=PAdmin_SWC_DIDMgr_vRoE_Activation_State}
        {enable-take-address=true, indirect-api=false, port-defined-argument-value{value=53, value-type=NvM_BlockIdType}, port=PS_SWC_ProxiConfigMgrProxiConfigTable}
        {enable-take-address=true, indirect-api=false, port-defined-argument-value{value=53, value-type=NvM_BlockIdType}, port=PAdmin_SWC_ProxiConfigMgrProxiConfigTable}
        {enable-take-address=true, indirect-api=false, port-defined-argument-value{value=54, value-type=NvM_BlockIdType}, port=PS_SWC_ProxiConfigMgrProxiErrorData}
        {enable-take-address=true, indirect-api=false, port-defined-argument-value{value=54, value-type=NvM_BlockIdType}, port=PAdmin_SWC_ProxiConfigMgrProxiErrorData}
        {enable-take-address=true, indirect-api=false, port-defined-argument-value{value=57, value-type=NvM_BlockIdType}, port=PS_SWC_PartNumMgrDID_FD31_EOLCodingState}
        {enable-take-address=true, indirect-api=false, port-defined-argument-value{value=57, value-type=NvM_BlockIdType}, port=PAdmin_SWC_PartNumMgrDID_FD31_EOLCodingState}
        {enable-take-address=true, indirect-api=false, port-defined-argument-value{value=24, value-type=NvM_BlockIdType}, port=PS_SWC_PartNumMgrDID_F110_Ecu_Diag_Info}
        {enable-take-address=true, indirect-api=false, port-defined-argument-value{value=24, value-type=NvM_BlockIdType}, port=PAdmin_SWC_PartNumMgrDID_F110_Ecu_Diag_Info}
        {enable-take-address=true, indirect-api=false, port-defined-argument-value{value=21, value-type=NvM_BlockIdType}, port=PS_SWC_PartNumMgrDID_F132_EBOM_Ecu_PartNum}
        {enable-take-address=true, indirect-api=false, port-defined-argument-value{value=21, value-type=NvM_BlockIdType}, port=PAdmin_SWC_PartNumMgrDID_F132_EBOM_Ecu_PartNum}
        {enable-take-address=true, indirect-api=false, port-defined-argument-value{value=16, value-type=NvM_BlockIdType}, port=PS_SWC_PartNumMgrDID_F133_EBOM_Asm_PartNum}
        {enable-take-address=true, indirect-api=false, port-defined-argument-value{value=16, value-type=NvM_BlockIdType}, port=PAdmin_SWC_PartNumMgrDID_F133_EBOM_Asm_PartNum}
        {enable-take-address=true, indirect-api=false, port-defined-argument-value{value=20, value-type=NvM_BlockIdType}, port=PS_SWC_PartNumMgrDID_F134_CODEP_Asm_PartNum}
        {enable-take-address=true, indirect-api=false, port-defined-argument-value{value=20, value-type=NvM_BlockIdType}, port=PAdmin_SWC_PartNumMgrDID_F134_CODEP_Asm_PartNum}
        {enable-take-address=true, indirect-api=false, port-defined-argument-value{value=19, value-type=NvM_BlockIdType}, port=PS_SWC_PartNumMgrDID_F187_CODEP_Ecu_PartNum}
        {enable-take-address=true, indirect-api=false, port-defined-argument-value{value=19, value-type=NvM_BlockIdType}, port=PAdmin_SWC_PartNumMgrDID_F187_CODEP_Ecu_PartNum}
        {enable-take-address=true, indirect-api=false, port-defined-argument-value{value=15, value-type=NvM_BlockIdType}, port=PS_SWC_PartNumMgrDID_F188_FCA_ESLM_Ecu_SW_Num}
        {enable-take-address=true, indirect-api=false, port-defined-argument-value{value=15, value-type=NvM_BlockIdType}, port=PAdmin_SWC_PartNumMgrDID_F188_FCA_ESLM_Ecu_SW_Num}
        {enable-take-address=true, indirect-api=false, port-defined-argument-value{value=17, value-type=NvM_BlockIdType}, port=PS_SWC_PartNumMgrDID_F18A_FCA_ESLM_Ecu_SW_Cal_Num}
        {enable-take-address=true, indirect-api=false, port-defined-argument-value{value=17, value-type=NvM_BlockIdType}, port=PAdmin_SWC_PartNumMgrDID_F18A_FCA_ESLM_Ecu_SW_Cal_Num}
        {enable-take-address=true, indirect-api=false, port-defined-argument-value{value=18, value-type=NvM_BlockIdType}, port=PS_SWC_PartNumMgrDID_F18B_FCA_ESLM_ECU_SW_App_Num}
        {enable-take-address=true, indirect-api=false, port-defined-argument-value{value=18, value-type=NvM_BlockIdType}, port=PAdmin_SWC_PartNumMgrDID_F18B_FCA_ESLM_ECU_SW_App_Num}
        {enable-take-address=true, indirect-api=false, port-defined-argument-value{value=22, value-type=NvM_BlockIdType}, port=PS_SWC_PartNumMgrDID_F194_Supplier_Ecu_SW_PartNum}
        {enable-take-address=true, indirect-api=false, port-defined-argument-value{value=22, value-type=NvM_BlockIdType}, port=PAdmin_SWC_PartNumMgrDID_F194_Supplier_Ecu_SW_PartNum}
        {enable-take-address=true, indirect-api=false, port-defined-argument-value{value=23, value-type=NvM_BlockIdType}, port=PS_SWC_PartNumMgrDID_F195_Supplier_Ecu_SW_VerNum}
        {enable-take-address=true, indirect-api=false, port-defined-argument-value{value=23, value-type=NvM_BlockIdType}, port=PAdmin_SWC_PartNumMgrDID_F195_Supplier_Ecu_SW_VerNum}
        {enable-take-address=true, indirect-api=false, port-defined-argument-value{value=58, value-type=NvM_BlockIdType}, port=PS_CalDataProviderSVSCamCurrentCalibData}
        {enable-take-address=true, indirect-api=false, port-defined-argument-value{value=58, value-type=NvM_BlockIdType}, port=PAdmin_CalDataProviderSVSCamCurrentCalibData}
        {enable-take-address=true, indirect-api=false, port-defined-argument-value{value=59, value-type=NvM_BlockIdType}, port=PS_CalDataProviderSVSCamEOLCalibData}
        {enable-take-address=true, indirect-api=false, port-defined-argument-value{value=59, value-type=NvM_BlockIdType}, port=PAdmin_CalDataProviderSVSCamEOLCalibData}
        {enable-take-address=true, indirect-api=false, port-defined-argument-value{value=60, value-type=NvM_BlockIdType}, port=PS_CalDataProviderSVSCamOCCalibData}
        {enable-take-address=true, indirect-api=false, port-defined-argument-value{value=60, value-type=NvM_BlockIdType}, port=PAdmin_CalDataProviderSVSCamOCCalibData}
        {enable-take-address=true, indirect-api=false, port-defined-argument-value{value=61, value-type=NvM_BlockIdType}, port=PS_CalDataProviderSVSCamSCCalibData}
        {enable-take-address=true, indirect-api=false, port-defined-argument-value{value=61, value-type=NvM_BlockIdType}, port=PAdmin_CalDataProviderSVSCamSCCalibData}
        {enable-take-address=true, indirect-api=false, port-defined-argument-value{value=62, value-type=NvM_BlockIdType}, port=PS_SWC_PartNumMgrUssSensorMarrData}
        {enable-take-address=true, indirect-api=false, port-defined-argument-value{value=62, value-type=NvM_BlockIdType}, port=PAdmin_SWC_PartNumMgrUssSensorMarrData}
        {enable-take-address=true, indirect-api=false, port-defined-argument-value{value=63, value-type=NvM_BlockIdType}, port=PS_SWC_DIDMgrDID_FD01_PrevCalibDataCopy}
        {enable-take-address=true, indirect-api=false, port-defined-argument-value{value=63, value-type=NvM_BlockIdType}, port=PAdmin_SWC_DIDMgrDID_FD01_PrevCalibDataCopy}
        {enable-take-address=true, indirect-api=false, port-defined-argument-value{value=64, value-type=NvM_BlockIdType}, port=PS_SWC_DIDMgrDID_FD42_FailsafeDebug}
        {enable-take-address=true, indirect-api=false, port-defined-argument-value{value=64, value-type=NvM_BlockIdType}, port=PAdmin_SWC_DIDMgrDID_FD42_FailsafeDebug}
        {enable-take-address=true, indirect-api=false, port-defined-argument-value{value=65, value-type=NvM_BlockIdType}, port=PS_SWC_DIDMgrDID_RearBrakeEvent}
        {enable-take-address=true, indirect-api=false, port-defined-argument-value{value=65, value-type=NvM_BlockIdType}, port=PAdmin_SWC_DIDMgrDID_RearBrakeEvent}
        {enable-take-address=true, indirect-api=false, port-defined-argument-value{value=66, value-type=NvM_BlockIdType}, port=PS_SWC_DIDMgrDID_SPMAbrtEvent}
        {enable-take-address=true, indirect-api=false, port-defined-argument-value{value=66, value-type=NvM_BlockIdType}, port=PAdmin_SWC_DIDMgrDID_SPMAbrtEvent}
        {enable-take-address=true, indirect-api=false, port-defined-argument-value{value=67, value-type=NvM_BlockIdType}, port=PS_CDD_IPCHandlerFeatureAP_HMI_NvMData}
        {enable-take-address=true, indirect-api=false, port-defined-argument-value{value=67, value-type=NvM_BlockIdType}, port=PAdmin_CDD_IPCHandlerFeatureAP_HMI_NvMData}
        {enable-take-address=true, indirect-api=false, port-defined-argument-value{value=70, value-type=NvM_BlockIdType}, port=PS_SWC_DIDMgrDID_FD86_FunctionalSettings}
        {enable-take-address=true, indirect-api=false, port-defined-argument-value{value=70, value-type=NvM_BlockIdType}, port=PAdmin_SWC_DIDMgrDID_FD86_FunctionalSettings}
        {enable-take-address=true, indirect-api=false, port-defined-argument-value{value=40, value-type=NvM_BlockIdType}, port=PS_SWC_DIDMgrDID_2939_WakeupReason}
        {enable-take-address=true, indirect-api=false, port-defined-argument-value{value=40, value-type=NvM_BlockIdType}, port=PAdmin_SWC_DIDMgrDID_2939_WakeupReason}
        {enable-take-address=true, indirect-api=false, port-defined-argument-value{value=41, value-type=NvM_BlockIdType}, port=PS_SWC_DIDMgrDID_FDF0_SleepProcess}
        {enable-take-address=true, indirect-api=false, port-defined-argument-value{value=41, value-type=NvM_BlockIdType}, port=PAdmin_SWC_DIDMgrDID_FDF0_SleepProcess}
        {enable-take-address=true, indirect-api=false, port-defined-argument-value{value=42, value-type=NvM_BlockIdType}, port=PS_SWC_RIDMgrDID_5201_PlantModeStatus}
        {enable-take-address=true, indirect-api=false, port-defined-argument-value{value=42, value-type=NvM_BlockIdType}, port=PAdmin_SWC_RIDMgrDID_5201_PlantModeStatus}
        {enable-take-address=true, indirect-api=false, port-defined-argument-value{value=43, value-type=NvM_BlockIdType}, port=PS_SWC_RIDMgrVIN_CurrentVal}
        {enable-take-address=true, indirect-api=false, port-defined-argument-value{value=43, value-type=NvM_BlockIdType}, port=PAdmin_SWC_RIDMgrVIN_CurrentVal}
        {enable-take-address=true, indirect-api=false, port-defined-argument-value{value=44, value-type=NvM_BlockIdType}, port=PS_SWC_RIDMgrVIN_Lock}
        {enable-take-address=true, indirect-api=false, port-defined-argument-value{value=44, value-type=NvM_BlockIdType}, port=PAdmin_SWC_RIDMgrVIN_Lock}
        {enable-take-address=true, indirect-api=false, port-defined-argument-value{value=45, value-type=NvM_BlockIdType}, port=PS_SWC_RIDMgrVIN_OdometerCnt}
        {enable-take-address=true, indirect-api=false, port-defined-argument-value{value=45, value-type=NvM_BlockIdType}, port=PAdmin_SWC_RIDMgrVIN_OdometerCnt}
        {enable-take-address=true, indirect-api=false, port-defined-argument-value{value=26, value-type=NvM_BlockIdType}, port=PS_SWC_RIDMgrVIN_OriginalVal}
        {enable-take-address=true, indirect-api=false, port-defined-argument-value{value=26, value-type=NvM_BlockIdType}, port=PAdmin_SWC_RIDMgrVIN_OriginalVal}
        {enable-take-address=true, indirect-api=false, port-defined-argument-value{value=13, value-type=NvM_BlockIdType}, port=PS_NvMBlockDescriptor_FileHeader}
        {enable-take-address=true, indirect-api=false, port-defined-argument-value{value=13, value-type=NvM_BlockIdType}, port=PAdmin_NvMBlockDescriptor_FileHeader}
        enable-take-address=true, indirect-api=false, port=NvM_RpNotifyJobEnd_NvMBlockDescriptor_FileHeader
        {enable-take-address=true, indirect-api=false, port-defined-argument-value{value=71, value-type=NvM_BlockIdType}, port=PS_CDD_IPCHandlerFPA_SlotData}
        {enable-take-address=true, indirect-api=false, port-defined-argument-value{value=71, value-type=NvM_BlockIdType}, port=PAdmin_CDD_IPCHandlerFPA_SlotData}
        {enable-take-address=true, indirect-api=false, port-defined-argument-value{value=3, value-type=NvM_BlockIdType}, port=PS_CDD_CryptoMgrNvMBlockDescriptor_SecAccessDelayFlag}
        {enable-take-address=true, indirect-api=false, port-defined-argument-value{value=3, value-type=NvM_BlockIdType}, port=PAdmin_CDD_CryptoMgrNvMBlockDescriptor_SecAccessDelayFlag}
        {enable-take-address=true, indirect-api=false, port-defined-argument-value{value=4, value-type=NvM_BlockIdType}, port=PS_CDD_CryptoMgrNvMBlockDescriptor_SecAccessInvalidCount}
        {enable-take-address=true, indirect-api=false, port-defined-argument-value{value=4, value-type=NvM_BlockIdType}, port=PAdmin_CDD_CryptoMgrNvMBlockDescriptor_SecAccessInvalidCount}
        {enable-take-address=true, indirect-api=false, port-defined-argument-value{value=14, value-type=NvM_BlockIdType}, port=PS_NvMBlockDescriptor_CertAccessInfo}
        {enable-take-address=true, indirect-api=false, port-defined-argument-value{value=14, value-type=NvM_BlockIdType}, port=PAdmin_NvMBlockDescriptor_CertAccessInfo}
        enable-take-address=true, indirect-api=false, port=NvM_RpNotifyJobEnd_NvMBlockDescriptor_CertAccessInfo
        {enable-take-address=true, indirect-api=false, port-defined-argument-value{value=68, value-type=NvM_BlockIdType}, port=PS_CDD_CryptoMgrNvMBlockDescriptor_SecureLogGroup1}
        {enable-take-address=true, indirect-api=false, port-defined-argument-value{value=68, value-type=NvM_BlockIdType}, port=PAdmin_CDD_CryptoMgrNvMBlockDescriptor_SecureLogGroup1}
        {enable-take-address=true, indirect-api=false, port-defined-argument-value{value=69, value-type=NvM_BlockIdType}, port=PS_CDD_CryptoMgrNvMBlockDescriptor_SecureLogGroup2}
        {enable-take-address=true, indirect-api=false, port-defined-argument-value{value=69, value-type=NvM_BlockIdType}, port=PAdmin_CDD_CryptoMgrNvMBlockDescriptor_SecureLogGroup2}
        {enable-take-address=true, indirect-api=false, port-defined-argument-value{value=72, value-type=NvM_BlockIdType}, port=PS_Safety_GuardSafeStat2_ResetReason}
        {enable-take-address=true, indirect-api=false, port-defined-argument-value{value=72, value-type=NvM_BlockIdType}, port=PAdmin_Safety_GuardSafeStat2_ResetReason}
        {enable-take-address=true, indirect-api=false, port-defined-argument-value{value=73, value-type=NvM_BlockIdType}, port=PS_CalDataProviderFrontCamSerialNumber}
        {enable-take-address=true, indirect-api=false, port-defined-argument-value{value=73, value-type=NvM_BlockIdType}, port=PAdmin_CalDataProviderFrontCamSerialNumber}
        {enable-take-address=true, indirect-api=false, port-defined-argument-value{value=74, value-type=NvM_BlockIdType}, port=PS_CalDataProviderLeftCamSerialNumber}
        {enable-take-address=true, indirect-api=false, port-defined-argument-value{value=74, value-type=NvM_BlockIdType}, port=PAdmin_CalDataProviderLeftCamSerialNumber}
        {enable-take-address=true, indirect-api=false, port-defined-argument-value{value=75, value-type=NvM_BlockIdType}, port=PS_CalDataProviderRearCamSerialNumber}
        {enable-take-address=true, indirect-api=false, port-defined-argument-value{value=75, value-type=NvM_BlockIdType}, port=PAdmin_CalDataProviderRearCamSerialNumber}
        {enable-take-address=true, indirect-api=false, port-defined-argument-value{value=76, value-type=NvM_BlockIdType}, port=PS_CalDataProviderRightCamSerialNumber}
        {enable-take-address=true, indirect-api=false, port-defined-argument-value{value=76, value-type=NvM_BlockIdType}, port=PAdmin_CalDataProviderRightCamSerialNumber}
        {enable-take-address=true, indirect-api=false, port-defined-argument-value{value=79, value-type=NvM_BlockIdType}, port=PS_CDD_SafetyCDD_PMICLastResetReason_BISTStatus}
        {enable-take-address=true, indirect-api=false, port-defined-argument-value{value=79, value-type=NvM_BlockIdType}, port=PAdmin_CDD_SafetyCDD_PMICLastResetReason_BISTStatus}
        {enable-take-address=true, indirect-api=false, port-defined-argument-value{value=81, value-type=NvM_BlockIdType}, port=PS_SWC_DIDMgrDID_FD74_BuffMarkCompErr}
        {enable-take-address=true, indirect-api=false, port-defined-argument-value{value=81, value-type=NvM_BlockIdType}, port=PAdmin_SWC_DIDMgrDID_FD74_BuffMarkCompErr}
        {enable-take-address=true, indirect-api=false, port-defined-argument-value{value=82, value-type=NvM_BlockIdType}, port=PS_SWC_DIDMgrDID_FD74_PHY_TuningErr}
        {enable-take-address=true, indirect-api=false, port-defined-argument-value{value=82, value-type=NvM_BlockIdType}, port=PAdmin_SWC_DIDMgrDID_FD74_PHY_TuningErr}
        {enable-take-address=true, indirect-api=false, port-defined-argument-value{value=83, value-type=NvM_BlockIdType}, port=PAdmin_SWC_DTCMgrDTC_APARequestSts_PAMRequestSts}
        {enable-take-address=true, indirect-api=false, port-defined-argument-value{value=83, value-type=NvM_BlockIdType}, port=PS_SWC_DTCMgrDTC_APARequestSts_PAMRequestSts}
      11 x runnable:
        NvM_MainFunction
          sync call OpServerCallNvM_MainFunction_JobFinished_NvM_RpNotifyJobEnd_NvMBlockDescriptor_MetaData: operation=NvM_RpNotifyJobEnd_NvMBlockDescriptor_MetaData.JobFinished, timeout=0
          sync call OpServerCallNvM_MainFunction_JobFinished_NvM_RpNotifyJobEnd_NvMBlockDescriptor_FileHeader: operation=NvM_RpNotifyJobEnd_NvMBlockDescriptor_FileHeader.JobFinished, timeout=0
          sync call OpServerCallNvM_MainFunction_JobFinished_NvM_RpNotifyJobEnd_NvMBlockDescriptor_CertAccessInfo: operation=NvM_RpNotifyJobEnd_NvMBlockDescriptor_CertAccessInfo.JobFinished, timeout=0
        GetErrorStatus: can-be-invoked-concurrently=true, symbol=NvM_GetErrorStatus
        SetRamBlockStatus: can-be-invoked-concurrently=true, symbol=NvM_SetRamBlockStatus
        ReadBlock: can-be-invoked-concurrently=true, symbol=NvM_ReadBlock
        WriteBlock: can-be-invoked-concurrently=true, symbol=NvM_WriteBlock
        SetDataIndex: can-be-invoked-concurrently=true, symbol=NvM_SetDataIndex
        GetDataIndex: can-be-invoked-concurrently=true, symbol=NvM_GetDataIndex
        InvalidateNvBlock: can-be-invoked-concurrently=true, symbol=NvM_InvalidateNvBlock
        EraseBlock: can-be-invoked-concurrently=true, symbol=NvM_EraseNvBlock
        SetBlockProtection: can-be-invoked-concurrently=true, symbol=NvM_SetBlockProtection
        RestoreBlockDefaults: can-be-invoked-concurrently=true, symbol=NvM_RestoreBlockDefaults
  swc implementation NvMImplementation: programming-language=C, behavior=NvMInternalBehavior
